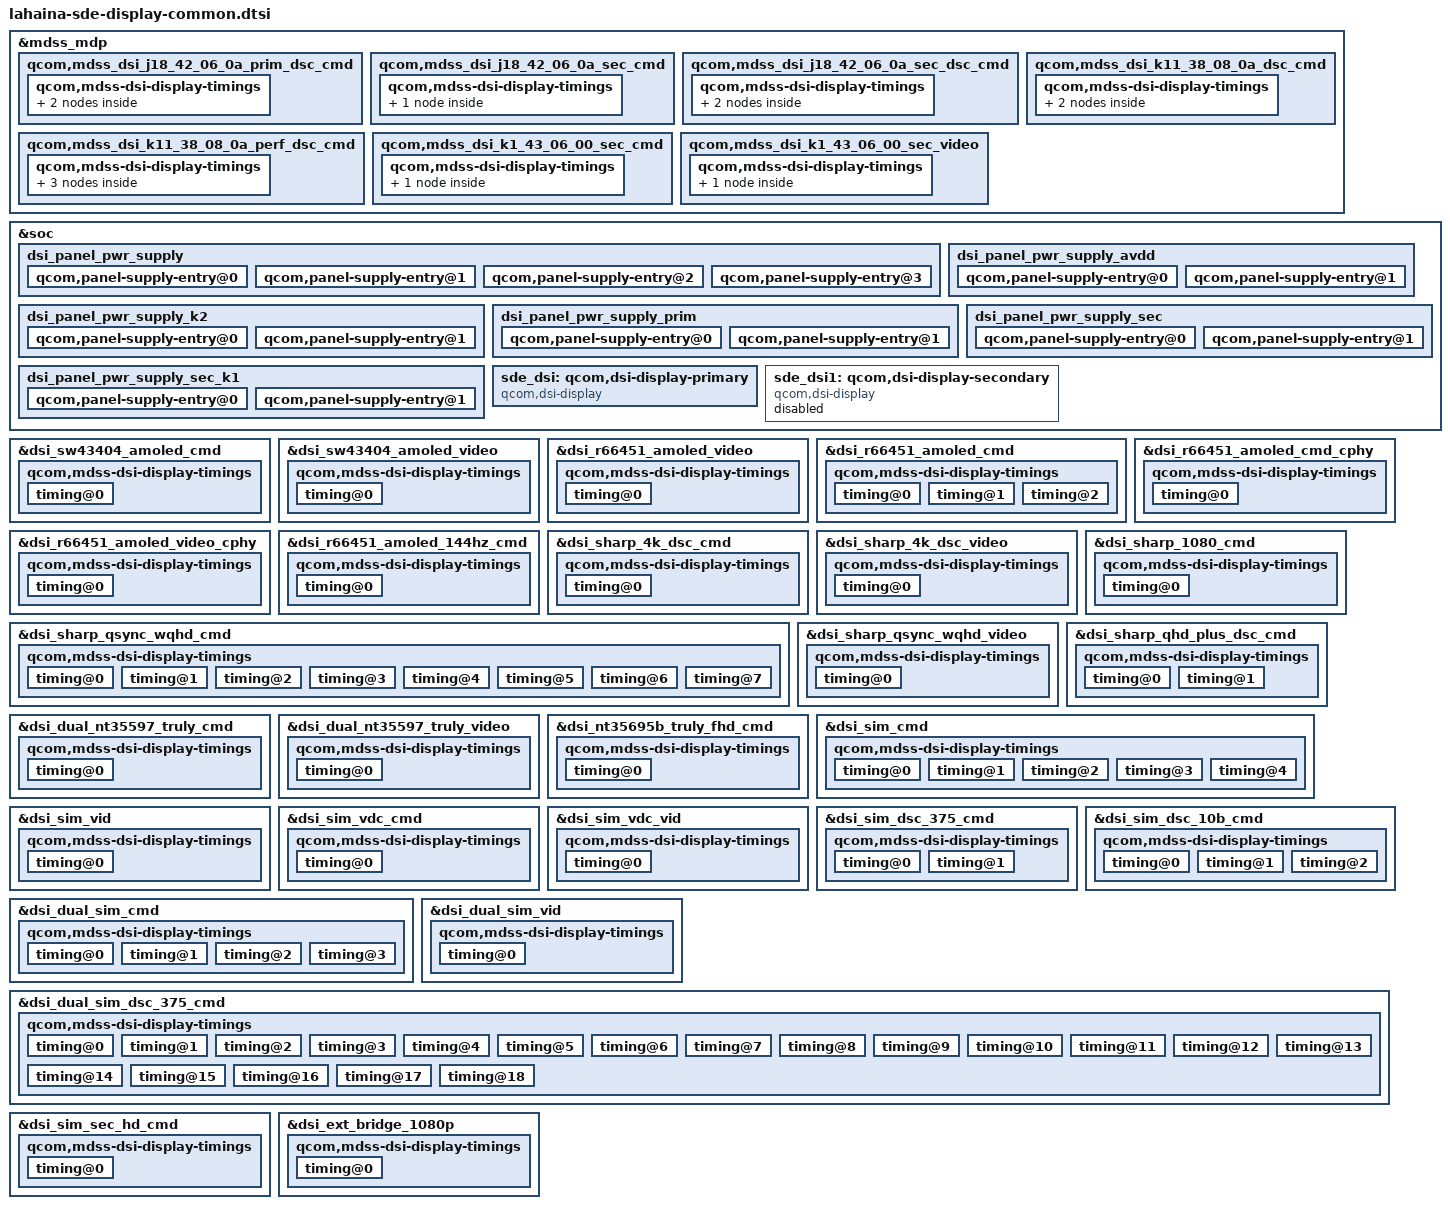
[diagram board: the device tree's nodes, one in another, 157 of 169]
#include "dsi-panel-sw43404-amoled-dsc-wqhd-cmd.dtsi"
#include "dsi-panel-sw43404-amoled-dsc-wqhd-video.dtsi"
#include "dsi-panel-sw43404-amoled-dsc-fhd-plus-cmd.dtsi"
#include "dsi-panel-sharp-dsc-4k-cmd.dtsi"
#include "dsi-panel-sharp-dsc-4k-video.dtsi"
#include "dsi-panel-sharp-dsc-qhd-plus-cmd.dtsi"
#include "dsi-panel-sharp-qsync-wqhd-cmd.dtsi"
#include "dsi-panel-sharp-qsync-wqhd-video.dtsi"
#include "dsi-panel-sharp-1080p-cmd.dtsi"
#include "dsi-panel-nt35597-truly-dualmipi-wqxga-cmd.dtsi"
#include "dsi-panel-nt35597-truly-dualmipi-wqxga-video.dtsi"
#include "dsi-panel-nt35695b-truly-fhd-cmd.dtsi"
#include "dsi-panel-nt35695b-truly-fhd-video.dtsi"
#include "dsi-panel-r66451-dsc-fhd-plus-video-cphy.dtsi"
#include "dsi-panel-r66451-dsc-fhd-plus-cmd-cphy.dtsi"
#include "dsi-panel-r66451-dsc-fhd-plus-video.dtsi"
#include "dsi-panel-r66451-dsc-fhd-plus-cmd.dtsi"
#include "dsi-panel-r66451-dsc-fhd-plus-144hz-cmd.dtsi"
#include "dsi-panel-ext-bridge-1080p.dtsi"
#include "dsi-panel-sim-cmd.dtsi"
#include "dsi-panel-sim-video.dtsi"
#include "dsi-panel-sim-dsc375-cmd.dtsi"
#include "dsi-panel-sim-dsc-10bit-cmd.dtsi"
#include "dsi-panel-sim-dualmipi-cmd.dtsi"
#include "dsi-panel-sim-dualmipi-video.dtsi"
#include "dsi-panel-sim-dualmipi-dsc375-cmd.dtsi"
#include "dsi-panel-sim-sec-hd-cmd.dtsi"
#include <dt-bindings/clock/mdss-5nm-pll-clk.h>
#include "dsi-panel-sim-vdc-vid.dtsi"
#include "dsi-panel-sim-vdc-cmd.dtsi"
#include "dsi-panel-k2-38-0c-00-dsc-cmd.dtsi"
#include "dsi-panel-k2-38-08-0a-dsc-cmd.dtsi"
#include "dsi-panel-k2-38-08-0a-mp-dsc-cmd.dtsi"
#include "dsi-panel-k2b-38-08-0a-dsc-cmd.dtsi"

&mdss_mdp {
	qcom,mdss_dsi_j18_42_06_0a_prim_dsc_cmd {
		qcom,mdss-dsi-panel-name = "xiaomi 42 06 0a cmd mode dsc primary dsi panel";
		qcom,mdss-dsi-panel-type = "dsi_cmd_mode";
		qcom,mdss-dsi-virtual-channel-id = <0x0>;
		qcom,mdss-dsi-stream = <0x0>;
		qcom,mdss-dsi-bpp = <0x18>;
		qcom,mdss-dsi-color-order = "rgb_swap_rgb";
		qcom,mdss-dsi-underflow-color = <0xff>;
		qcom,mdss-dsi-border-color = <0x0>;
		qcom,dsi-ctrl-num = <0x0>;
		qcom,dsi-phy-num = <0x0>;
		qcom,mdss-dsi-traffic-mode = "burst_mode";
		qcom,mdss-dsi-lane-map = "lane_map_0123";
		qcom,mdss-dsi-bllp-eof-power-mode;
		qcom,mdss-dsi-bllp-power-mode;
		qcom,mdss-dsi-lane-0-state;
		qcom,mdss-dsi-lane-1-state;
		qcom,mdss-dsi-lane-2-state;
		qcom,mdss-dsi-lane-3-state;
		qcom,mdss-dsi-dma-trigger = "trigger_sw";
		qcom,mdss-dsi-mdp-trigger = "none";
		qcom,mdss-dsi-reset-sequence = <0x1 0x1 0x0 0x1 0x1 0xf>;
		qcom,mdss-pan-physical-width-dimension = <0x7a>;
		qcom,mdss-pan-physical-height-dimension = <0xa3>;
		qcom,mdss-dsi-te-pin-select = <0x1>;
		qcom,mdss-dsi-wr-mem-start = <0x2c>;
		qcom,mdss-dsi-wr-mem-continue = <0x3c>;
		qcom,mdss-dsi-te-dcs-command = <0x1>;
		qcom,mdss-dsi-te-check-enable;
		qcom,mdss-dsi-te-using-te-pin;
		qcom,mdss-dsi-tx-eot-append;
		qcom,mdss-dsi-lp11-init;
		qcom,mdss-dsi-bl-inverted-dbv;
		qcom,mdss-dsi-panel-hdr-enabled;
		qcom,mdss-dsi-panel-hdr-color-primaries = <0x38a4 0x3c8c 0x7d00 0x4268 0x3c8c 0x7530 0x1f40 0xbb8>;
		qcom,mdss-dsi-panel-peak-brightness = <0x401640>;
		qcom,mdss-dsi-panel-blackness-level = <0xc9e>;
		qcom,bl-update-flag = "delay_until_first_frame";
		mi,aod-bl-51ctl-flag;
		mi,esd-err-irq-gpio = <0xffffffff 0x43 0x2001>;
		qcom,dsi-select-clocks = "mux_byte_clk0", "mux_pixel_clk0";
		qcom,panel-supply-entries = <0x23>;
		qcom,mdss-dsi-bl-pmic-control-type = "bl_ctrl_dcs";
		qcom,mdss-dsi-bl-min-level = <0x2>;
		qcom,mdss-dsi-bl-max-level = <0x7ff>;
		qcom,mdss-brightness-max-level = <0x7ff>;
		qcom,platform-te-gpio = <0xffffffff 0x52 0x0>;
		qcom,platform-reset-gpio = <0xffffffff 0x18 0x0>;

		qcom,mdss-dsi-display-timings {

			timing@0 {
				qcom,mdss-dsi-panel-framerate = <0x3c>;
				qcom,mdss-dsi-panel-width = <0x9b0>;
				qcom,mdss-dsi-panel-height = <0x744>;
				qcom,mdss-dsi-h-front-porch = <0xc>;
				qcom,mdss-dsi-h-back-porch = <0xc>;
				qcom,mdss-dsi-h-pulse-width = <0x4>;
				qcom,mdss-dsi-h-sync-skew = <0x0>;
				qcom,mdss-dsi-v-back-porch = <0x7>;
				qcom,mdss-dsi-v-front-porch = <0x17>;
				qcom,mdss-dsi-v-pulse-width = <0x2>;
				qcom,mdss-dsi-h-sync-pulse = <0x0>;
				qcom,mdss-dsi-h-left-border = <0x0>;
				qcom,mdss-dsi-h-right-border = <0x0>;
				qcom,mdss-dsi-v-top-border = <0x0>;
				qcom,mdss-dsi-v-bottom-border = <0x0>;
				qcom,mdss-dsi-panel-clockrate = <0x23c34600>;
				qcom,mdss-dsi-panel-jitter = <0x5 0x1>;
				qcom,mdss-dsi-on-command = [15 00 00 00 00 00 02 fe 00 15 00 00 00 00 00 02 fa 01 15 00 00 00 00 00 02 fe 40 15 00 00 00 00 00 02 40 06 15 00 00 00 00 00 02 fe d2 15 00 00 00 00 00 02 36 83 15 00 00 00 00 00 02 37 0c 15 00 00 00 00 00 02 fe 00 15 00 00 00 00 00 02 c2 08 15 00 00 00 00 00 02 35 00 39 01 00 00 00 00 03 51 07 ff 05 01 00 00 78 00 02 11 00 05 01 00 00 1e 00 02 29 00];
				qcom,mdss-dsi-off-command = [05 01 00 00 0a 00 02 28 00 05 01 00 00 78 00 02 10 00];
				qcom,mdss-dsi-on-command-state = "dsi_lp_mode";
				qcom,mdss-dsi-off-command-state = "dsi_lp_mode";
				qcom,mdss-dsi-lp1-command = [05 01 00 00 00 00 02 39 00];
				qcom,mdss-dsi-lp1-command-state = "dsi_lp_mode";
				qcom,mdss-dsi-nolp-command = [05 01 00 00 00 00 02 38 00];
				qcom,mdss-dsi-nolp-command-state = "dsi_lp_mode";
				qcom,compression-mode = "dsc";
				qcom,mdss-dsc-slice-height = <0x3a2>;
				qcom,mdss-dsc-slice-width = <0x4d8>;
				qcom,mdss-dsc-slice-per-pkt = <0x2>;
				qcom,mdss-dsc-bit-per-component = <0x8>;
				qcom,mdss-dsc-bit-per-pixel = <0x8>;
				qcom,mdss-dsc-block-prediction-enable;
				mi,mdss-dsi-flat-on-command = [39 00 00 00 00 00 02 fe 98 39 00 00 00 00 00 02 17 fe 39 00 00 00 00 00 02 18 7f 39 00 00 00 00 00 02 27 20 39 00 00 00 00 00 02 fe 40 39 00 00 00 00 00 02 bd 05 39 00 00 00 00 00 02 fe f2 39 00 00 00 00 00 02 e0 00 39 00 00 00 00 00 02 fe 98 39 00 00 00 00 00 02 18 7f 39 01 00 00 00 00 02 1c 04];
				mi,mdss-dsi-flat-off-command = [39 00 00 00 00 00 02 fe 98 39 00 00 00 00 00 02 17 fe 39 00 00 00 00 00 02 18 7f 39 00 00 00 00 00 02 27 20 39 00 00 00 00 00 02 fe 40 39 00 00 00 00 00 02 bd 00 39 00 00 00 00 00 02 fe f2 39 00 00 00 00 00 02 e0 00 39 00 00 00 00 00 02 fe 98 39 00 00 00 00 00 02 18 7f 39 01 00 00 00 00 02 1c 00];
				mi,mdss-dsi-flat-on-command-state = "dsi_hs_mode";
				mi,mdss-dsi-flat-off-command-state = "dsi_hs_mode";
				qcom,mdss-dsi-panel-phy-timings = [00 15 05 05 14 1f 05 05 06 02 04 00 13 0a];
				qcom,display-topology = <0x2 0x2 0x1>;
				qcom,default-topology-index = <0x0>;
			};

			timing@1 {
				qcom,mdss-dsi-panel-framerate = <0x5a>;
				qcom,mdss-dsi-panel-width = <0x9b0>;
				qcom,mdss-dsi-panel-height = <0x744>;
				qcom,mdss-dsi-h-front-porch = <0xc>;
				qcom,mdss-dsi-h-back-porch = <0xc>;
				qcom,mdss-dsi-h-pulse-width = <0x4>;
				qcom,mdss-dsi-h-sync-skew = <0x0>;
				qcom,mdss-dsi-v-back-porch = <0x6>;
				qcom,mdss-dsi-v-front-porch = <0x17>;
				qcom,mdss-dsi-v-pulse-width = <0x2>;
				qcom,mdss-dsi-h-sync-pulse = <0x0>;
				qcom,mdss-dsi-h-left-border = <0x0>;
				qcom,mdss-dsi-h-right-border = <0x0>;
				qcom,mdss-dsi-v-top-border = <0x0>;
				qcom,mdss-dsi-v-bottom-border = <0x0>;
				qcom,mdss-dsi-panel-clockrate = <0x23c34600>;
				qcom,mdss-dsi-panel-jitter = <0x5 0x1>;
				qcom,mdss-dsi-on-command = [15 00 00 00 00 00 02 fe 00 15 00 00 00 00 00 02 fa 01 15 00 00 00 00 00 02 fe 40 15 00 00 00 00 00 02 40 06 15 00 00 00 00 00 02 fe d2 15 00 00 00 00 00 02 36 83 15 00 00 00 00 00 02 37 0c 15 00 00 00 00 00 02 fe 00 15 00 00 00 00 00 02 c2 08 15 00 00 00 00 00 02 35 00 39 01 00 00 00 00 03 51 07 ff 05 01 00 00 78 00 02 11 00 05 01 00 00 1e 00 02 29 00];
				qcom,mdss-dsi-off-command = [05 01 00 00 0a 00 02 28 00 05 01 00 00 78 00 02 10 00];
				qcom,mdss-dsi-on-command-state = "dsi_lp_mode";
				qcom,mdss-dsi-off-command-state = "dsi_lp_mode";
				qcom,mdss-dsi-lp1-command = [05 01 00 00 00 00 02 39 00];
				qcom,mdss-dsi-lp1-command-state = "dsi_lp_mode";
				qcom,mdss-dsi-nolp-command = [05 01 00 00 00 00 02 38 00];
				qcom,mdss-dsi-nolp-command-state = "dsi_lp_mode";
				qcom,compression-mode = "dsc";
				qcom,mdss-dsc-slice-height = <0x3a2>;
				qcom,mdss-dsc-slice-width = <0x4d8>;
				qcom,mdss-dsc-slice-per-pkt = <0x2>;
				qcom,mdss-dsc-bit-per-component = <0x8>;
				qcom,mdss-dsc-bit-per-pixel = <0x8>;
				qcom,mdss-dsc-block-prediction-enable;
				qcom,mdss-dsi-panel-phy-timings = [00 15 05 05 14 1f 05 05 06 02 04 00 13 0a];
				qcom,display-topology = <0x2 0x2 0x1>;
				qcom,default-topology-index = <0x0>;
			};
		};
	};

	qcom,mdss_dsi_j18_42_06_0a_sec_cmd {
		qcom,mdss-dsi-panel-name = "xiaomi 42 06 0a cmd mode secondary dsi panel";
		qcom,mdss-dsi-panel-type = "dsi_cmd_mode";
		qcom,mdss-dsi-virtual-channel-id = <0x0>;
		qcom,mdss-dsi-stream = <0x0>;
		qcom,mdss-dsi-bpp = <0x18>;
		qcom,mdss-dsi-color-order = "rgb_swap_rgb";
		qcom,mdss-dsi-underflow-color = <0xff>;
		qcom,mdss-dsi-border-color = <0x0>;
		qcom,dsi-sec-ctrl-num = <0x1>;
		qcom,dsi-sec-phy-num = <0x1>;
		qcom,mdss-dsi-traffic-mode = "burst_mode";
		qcom,mdss-dsi-lane-map = "lane_map_0123";
		qcom,mdss-dsi-bllp-eof-power-mode;
		qcom,mdss-dsi-bllp-power-mode;
		qcom,mdss-dsi-lane-0-state;
		qcom,mdss-dsi-lane-1-state;
		qcom,mdss-dsi-lane-2-state;
		qcom,mdss-dsi-lane-3-state;
		qcom,mdss-dsi-dma-trigger = "trigger_sw";
		qcom,mdss-dsi-mdp-trigger = "none";
		qcom,mdss-dsi-reset-sequence = <0x1 0x1 0x0 0x1 0x1 0xf>;
		qcom,mdss-pan-physical-width-dimension = <0x34>;
		qcom,mdss-pan-physical-height-dimension = <0x9d>;
		qcom,mdss-dsi-te-pin-select = <0x1>;
		qcom,mdss-dsi-wr-mem-start = <0x2c>;
		qcom,mdss-dsi-wr-mem-continue = <0x3c>;
		qcom,mdss-dsi-te-dcs-command = <0x1>;
		qcom,mdss-dsi-te-check-enable;
		qcom,mdss-dsi-te-using-te-pin;
		qcom,mdss-dsi-tx-eot-append;
		qcom,mdss-dsi-lp11-init;
		qcom,mdss-dsi-bl-inverted-dbv;
		qcom,mdss-dsi-panel-hdr-enabled;
		qcom,mdss-dsi-panel-hdr-color-primaries = <0x38a4 0x3c8c 0x7d00 0x4268 0x3c8c 0x7530 0x1f40 0xbb8>;
		qcom,mdss-dsi-panel-peak-brightness = <0x401640>;
		qcom,mdss-dsi-panel-blackness-level = <0xc9e>;
		qcom,bl-update-flag = "delay_until_first_frame";
		qcom,dsi-select-sec-clocks = "mux_byte_clk1", "mux_pixel_clk1";
		qcom,panel-sec-supply-entries = <0x24>;
		qcom,mdss-dsi-sec-bl-pmic-control-type = "bl_ctrl_dcs";
		qcom,mdss-dsi-bl-min-level = <0x2>;
		qcom,mdss-dsi-bl-max-level = <0x7ff>;
		qcom,mdss-brightness-max-level = <0x7ff>;
		qcom,platform-te-gpio = <0xffffffff 0x53 0x0>;
		qcom,platform-sec-reset-gpio = <0xffffffff 0x4a 0x0>;

		qcom,mdss-dsi-display-timings {

			timing@0 {
				qcom,mdss-dsi-panel-framerate = <0x3c>;
				qcom,mdss-dsi-panel-width = <0x348>;
				qcom,mdss-dsi-panel-height = <0x9d8>;
				qcom,mdss-dsi-h-front-porch = <0x1c>;
				qcom,mdss-dsi-h-back-porch = <0x24>;
				qcom,mdss-dsi-h-pulse-width = <0x4>;
				qcom,mdss-dsi-h-sync-skew = <0x0>;
				qcom,mdss-dsi-v-back-porch = <0x14>;
				qcom,mdss-dsi-v-front-porch = <0x10>;
				qcom,mdss-dsi-v-pulse-width = <0x4>;
				qcom,mdss-dsi-h-sync-pulse = <0x0>;
				qcom,mdss-dsi-h-left-border = <0x0>;
				qcom,mdss-dsi-h-right-border = <0x0>;
				qcom,mdss-dsi-v-top-border = <0x0>;
				qcom,mdss-dsi-v-bottom-border = <0x0>;
				qcom,mdss-dsi-panel-clockrate = <0x338bcd00>;
				qcom,mdss-dsi-panel-jitter = <0x5 0x1>;
				qcom,mdss-dsi-on-command = [39 00 00 00 00 00 02 fe 60 39 00 00 00 00 00 02 95 ca 39 00 00 00 00 00 02 fe 00 39 00 00 00 00 00 02 5e 01 39 00 00 00 00 00 02 c2 08 39 00 00 00 00 00 02 35 00 39 01 00 00 00 00 03 51 07 ff 05 01 00 00 78 00 02 11 00 05 01 00 00 1e 00 02 29 00];
				qcom,mdss-dsi-off-command = [05 01 00 00 14 00 02 28 00 05 01 00 00 78 00 02 10 00];
				qcom,mdss-dsi-on-command-state = "dsi_lp_mode";
				qcom,mdss-dsi-off-command-state = "dsi_lp_mode";
				qcom,mdss-dsi-panel-phy-timings = [00 1d 07 07 17 22 07 07 08 02 04 00 19 0c];
				qcom,display-topology = <0x1 0x0 0x1>;
				qcom,default-topology-index = <0x0>;
			};
		};
	};

	qcom,mdss_dsi_j18_42_06_0a_sec_dsc_cmd {
		qcom,mdss-dsi-panel-name = "xiaomi 42 06 0a cmd mode dsc secondary dsi panel";
		qcom,mdss-dsi-panel-type = "dsi_cmd_mode";
		qcom,mdss-dsi-virtual-channel-id = <0x0>;
		qcom,mdss-dsi-stream = <0x0>;
		qcom,mdss-dsi-bpp = <0x18>;
		qcom,mdss-dsi-color-order = "rgb_swap_rgb";
		qcom,mdss-dsi-underflow-color = <0xff>;
		qcom,mdss-dsi-border-color = <0x0>;
		qcom,dsi-sec-ctrl-num = <0x1>;
		qcom,dsi-sec-phy-num = <0x1>;
		qcom,mdss-dsi-traffic-mode = "burst_mode";
		qcom,mdss-dsi-lane-map = "lane_map_0123";
		qcom,mdss-dsi-bllp-eof-power-mode;
		qcom,mdss-dsi-bllp-power-mode;
		qcom,mdss-dsi-lane-0-state;
		qcom,mdss-dsi-lane-1-state;
		qcom,mdss-dsi-lane-2-state;
		qcom,mdss-dsi-lane-3-state;
		qcom,mdss-dsi-dma-trigger = "trigger_sw";
		qcom,mdss-dsi-mdp-trigger = "none";
		qcom,mdss-dsi-reset-sequence = <0x1 0x1 0x0 0x1 0x1 0xf>;
		qcom,mdss-pan-physical-width-dimension = <0x34>;
		qcom,mdss-pan-physical-height-dimension = <0x9d>;
		qcom,mdss-dsi-te-pin-select = <0x1>;
		qcom,mdss-dsi-wr-mem-start = <0x2c>;
		qcom,mdss-dsi-wr-mem-continue = <0x3c>;
		qcom,mdss-dsi-te-dcs-command = <0x1>;
		qcom,mdss-dsi-te-check-enable;
		qcom,mdss-dsi-te-using-te-pin;
		qcom,mdss-dsi-tx-eot-append;
		qcom,mdss-dsi-lp11-init;
		qcom,mdss-dsi-bl-inverted-dbv;
		qcom,mdss-dsi-panel-hdr-enabled;
		qcom,mdss-dsi-panel-hdr-color-primaries = <0x38a4 0x3c8c 0x7d00 0x4268 0x3c8c 0x7530 0x1f40 0xbb8>;
		qcom,mdss-dsi-panel-peak-brightness = <0x401640>;
		qcom,mdss-dsi-panel-blackness-level = <0xc9e>;
		qcom,bl-update-flag = "delay_until_first_frame";
		mi,esd-err-irq-gpio = <0xffffffff 0x4b 0x2001>;
		mi,aod-nolp-command-enabled;
		mi,aod-bl-51ctl-flag;
		mi,mdss-dsi-panel-bl-dfps-enabled;
		mi,mdss-dsi-panel-bl-dfps-switch-threshold = <0x3b8>;
		mi,mdss-dsi-panel-dc-type = <0x0>;
		qcom,dsi-select-sec-clocks = "mux_byte_clk1", "mux_pixel_clk1";
		qcom,panel-sec-supply-entries = <0x24>;
		qcom,mdss-dsi-sec-bl-pmic-control-type = "bl_ctrl_dcs";
		qcom,mdss-dsi-bl-min-level = <0x2>;
		qcom,mdss-dsi-bl-max-level = <0x7ff>;
		qcom,mdss-brightness-max-level = <0x7ff>;
		qcom,platform-te-gpio = <0xffffffff 0x53 0x0>;
		qcom,platform-sec-reset-gpio = <0xffffffff 0x4a 0x0>;

		qcom,mdss-dsi-display-timings {

			timing@0 {
				qcom,mdss-dsi-panel-framerate = <0x3c>;
				qcom,mdss-dsi-panel-width = <0x348>;
				qcom,mdss-dsi-panel-height = <0x9d8>;
				qcom,mdss-dsi-h-front-porch = <0x1c>;
				qcom,mdss-dsi-h-back-porch = <0x24>;
				qcom,mdss-dsi-h-pulse-width = <0x4>;
				qcom,mdss-dsi-h-sync-skew = <0x0>;
				qcom,mdss-dsi-v-back-porch = <0x14>;
				qcom,mdss-dsi-v-front-porch = <0x10>;
				qcom,mdss-dsi-v-pulse-width = <0x4>;
				qcom,mdss-dsi-h-sync-pulse = <0x0>;
				qcom,mdss-dsi-h-left-border = <0x0>;
				qcom,mdss-dsi-h-right-border = <0x0>;
				qcom,mdss-dsi-v-top-border = <0x0>;
				qcom,mdss-dsi-v-bottom-border = <0x0>;
				qcom,mdss-dsi-panel-clockrate = <0x338bcd00>;
				qcom,mdss-dsi-panel-jitter = <0x5 0x1>;
				qcom,mdss-dsi-on-command = [39 00 00 00 00 00 02 fe 00 39 00 00 00 00 00 02 fa 01 39 00 00 00 00 00 02 fe e0 39 00 00 00 00 00 02 e7 00 39 00 00 00 00 00 02 fe d0 39 00 00 00 00 00 02 70 81 39 00 00 00 00 00 02 fe 60 39 00 00 00 00 00 02 c3 00 39 00 00 00 00 00 02 fe 74 39 00 00 00 00 00 02 0e ff 39 00 00 00 00 00 02 0f 00 39 00 00 00 00 00 02 10 14 39 00 00 00 00 00 02 11 14 39 00 00 00 00 00 02 12 13 39 00 00 00 00 00 02 13 12 39 00 00 00 00 00 02 14 11 39 00 00 00 00 00 02 15 10 39 00 00 00 00 00 02 16 0f 39 00 00 00 00 00 02 17 0e 39 00 00 00 00 00 02 18 0d 39 00 00 00 00 00 02 19 0c 39 00 00 00 00 00 02 fe 00 39 00 00 00 00 00 02 5e 01 39 00 00 00 00 00 02 c2 08 39 00 00 00 00 00 02 35 00 39 01 00 00 00 00 03 51 07 ff 05 01 00 00 78 00 02 11 00 05 01 00 00 1e 00 02 29 00];
				qcom,mdss-dsi-off-command = [05 01 00 00 14 00 02 28 00 05 01 00 00 78 00 02 10 00];
				qcom,mdss-dsi-on-command-state = "dsi_lp_mode";
				qcom,mdss-dsi-off-command-state = "dsi_lp_mode";
				qcom,mdss-dsi-timing-switch-command = [39 00 00 00 00 00 02 fe d0 39 00 00 00 00 00 02 70 81 39 00 00 00 00 00 02 fe 60 39 00 00 00 00 00 02 c3 00 39 00 00 00 00 00 02 fe 74 39 00 00 00 00 00 02 0e ff 39 00 00 00 00 00 02 0f 00 39 00 00 00 00 00 02 10 14 39 00 00 00 00 00 02 11 14 39 00 00 00 00 00 02 12 13 39 00 00 00 00 00 02 13 12 39 00 00 00 00 00 02 14 11 39 00 00 00 00 00 02 15 10 39 00 00 00 00 00 02 16 0f 39 00 00 00 00 00 02 17 0e 39 00 00 00 00 00 02 18 0d 39 00 00 00 00 00 02 19 0c 39 01 00 00 00 00 02 fe 00];
				qcom,mdss-dsi-timing-switch-command-state = "dsi_lp_mode";
				qcom,mdss-dsi-lp1-command = <0x39000000 0x2fe 0x60390000 0x2 0xc3003900 0x0 0x2fe0015 0x1000000 0x23900>;
				qcom,mdss-dsi-lp1-command-state = "dsi_lp_mode";
				qcom,mdss-dsi-nolp-command = [39 00 00 00 00 00 02 fe 00 15 00 00 00 00 00 02 38 00 39 00 00 00 00 00 02 fe 60 39 00 00 00 00 00 02 c3 00 39 01 00 00 00 00 02 fe 00];
				qcom,mdss-dsi-nolp-command-state = "dsi_lp_mode";
				qcom,compression-mode = "dsc";
				qcom,mdss-dsc-slice-height = <0x1a4>;
				qcom,mdss-dsc-slice-width = <0x348>;
				qcom,mdss-dsc-slice-per-pkt = <0x2>;
				qcom,mdss-dsc-bit-per-component = <0x8>;
				qcom,mdss-dsc-bit-per-pixel = <0x8>;
				qcom,mdss-dsc-block-prediction-enable;
				mi,mdss-dsi-timing-switch-command = [39 00 00 00 00 00 02 fe d0 39 00 00 00 00 00 02 70 81 39 00 00 00 00 00 02 fe 60 39 00 00 00 00 00 02 c3 08 39 00 00 00 00 00 02 fe 74 39 00 00 00 00 00 02 0e ff 39 00 00 00 00 00 02 0f 00 39 00 00 00 00 00 02 10 14 39 00 00 00 00 00 02 11 14 39 00 00 00 00 00 02 12 13 39 00 00 00 00 00 02 13 12 39 00 00 00 00 00 02 14 11 39 00 00 00 00 00 02 15 10 39 00 00 00 00 00 02 16 0f 39 00 00 00 00 00 02 17 0e 39 00 00 00 00 00 02 18 0d 39 00 00 00 00 00 02 19 0c 39 01 00 00 00 00 02 fe 00];
				mi,mdss-dsi-timing-switch-command-state = "dsi_lp_mode";
				mi,mdss-dsi-timing-switch-dc-lbm-command = <0x39000000 0x2fe 0x60390000 0x2 0xc3083900 0x0 0x2fe7439 0x0 0x20000 0x39000000 0x201 0x390000 0x2 0x2113900 0x0 0x2037339 0x0 0x2040f 0x39000000 0x205 0xa390000 0x2 0x6263900 0x0 0x2075f39 0x0 0x208be 0x39000000 0x209 0x1d390000 0x2 0xadc3900 0x0 0x20bb839 0x0 0x20cff 0x39000000 0x20d 0xff390000 0x2 0xeff3900 0x0 0x20f0039 0x0 0x21009 0x39000000 0x211 0x9390000 0x2 0x12083900 0x0 0x2130739 0x0 0x21406 0x39000000 0x215 0x5390000 0x2 0x16043900 0x0 0x2170339 0x0 0x21802 0x39000000 0x219 0x1390000 0x2 0x22ff3900 0x0 0x243ff39 0x0 0x24400 0x39000000 0x245 0x11390000 0x2 0x46113900 0x0 0x2474239 0x0 0x248f7 0x39000000 0x249 0xff390000 0x2 0x4a1f3900 0x0 0x24b1f39 0x0 0x24c1f 0x39000000 0x24d 0x1f390000 0x2 0x4ebc3900 0x0 0x24f5e39 0x0 0x2509e 0x39000000 0x251 0xff390000 0x2 0x52ff3900 0x0 0x253ff39 0x0 0x261ff 0x39000000 0x2fe 0x20390000 0x2 0xba053900 0x0 0x25d0239 0x0 0x2753f 0x39000000 0x276 0x3f390000 0x2 0x773f3900 0x0 0x2785a39 0x0 0x27a5a 0x39000000 0x27b 0x67390000 0x2 0x7c703901 0x0 0x27d7739 0x0 0x2fed0 0x39000000 0x270 0x81390000 0x2 0xfe603900 0x0 0x2c30839 0x0 0x2fe74 0x39000000 0x20e 0xff390000 0x2 0xf003900 0x0 0x2101439 0x0 0x21114 0x39000000 0x212 0x13390000 0x2 0x13123900 0x0 0x2141139 0x0 0x21510 0x39000000 0x216 0xf390000 0x2 0x170e3900 0x0 0x2180d39 0x1000000 0x2190c 0x39000000 0x2fe 0x60390000 0x2 0xc3003900 0x0 0x2fe7439 0x0 0x20000 0x39000000 0x201 0x390000 0x2 0x2003900 0x0 0x2037039 0x0 0x2040f 0x39000000 0x205 0x390000 0x2 0x6003900 0x0 0x2070039 0x0 0x20800 0x39000000 0x209 0x390000 0x2 0xa003900 0x0 0x20b0039 0x0 0x20cff 0x39000000 0x20d 0xff390000 0x2 0xe803900 0x0 0x20f0039 0x0 0x2100d 0x39000000 0x211 0x390000 0x2 0x12003900 0x0 0x2130039 0x0 0x21400 0x39000000 0x215 0x390000 0x2 0x16003900 0x0 0x2170039 0x0 0x2180d 0x39000000 0x219 0xc390000 0x2 0x22803900 0x0 0x2438039 0x0 0x24400 0x39000000 0x245 0xff390000 0x2 0x46ff3900 0x0 0x247ff39 0x0 0x248ff 0x39000000 0x249 0xff390000 0x2 0x4aff3900 0x0 0x24bff39 0x0 0x24cff 0x39000000 0x24d 0xff390000 0x2 0x4eff3900 0x0 0x24fff39 0x0 0x250ff 0x39000000 0x251 0xff390000 0x2 0x52ff3900 0x0 0x253ff39 0x0 0x26180 0x39000000 0x2fe 0x20390000 0x2 0xba033900 0x0 0x25d0239 0x0 0x2757f 0x39000000 0x276 0x7f390000 0x2 0x777f3900 0x0 0x2787f39 0x0 0x27a7f 0x39000000 0x27b 0x7f390000 0x2 0x7c7f3900 0x0 0x27d7f39 0x1000000 0x2fe00>;
				mi,mdss-dsi-timing-switch-dc-lbm-command-state = "dsi_lp_mode";
				mi,mdss-dsi-timing-switch-dc-hbm-command = <0x39000000 0x2fe 0x60390000 0x2 0xc3083900 0x0 0x2fe7439 0x0 0x20000 0x39000000 0x201 0x390000 0x2 0x2113900 0x0 0x2037339 0x0 0x2040f 0x39000000 0x205 0xa390000 0x2 0x6263900 0x0 0x2075f39 0x0 0x208be 0x39000000 0x209 0x1d390000 0x2 0xadc3900 0x0 0x20bb839 0x0 0x20cff 0x39000000 0x20d 0xff390000 0x2 0xeff3900 0x0 0x20f0039 0x0 0x21009 0x39000000 0x211 0x9390000 0x2 0x12083900 0x0 0x2130739 0x0 0x21406 0x39000000 0x215 0x5390000 0x2 0x16043900 0x0 0x2170339 0x0 0x21802 0x39000000 0x219 0x1390000 0x2 0x22ff3900 0x0 0x243ff39 0x0 0x24400 0x39000000 0x245 0x11390000 0x2 0x46113900 0x0 0x2474239 0x0 0x248f7 0x39000000 0x249 0xff390000 0x2 0x4a1f3900 0x0 0x24b1f39 0x0 0x24c1f 0x39000000 0x24d 0x1f390000 0x2 0x4ebc3900 0x0 0x24f5e39 0x0 0x2509e 0x39000000 0x251 0xff390000 0x2 0x52ff3900 0x0 0x253ff39 0x0 0x261ff 0x39000000 0x2fe 0x20390000 0x2 0xba053900 0x0 0x25d0239 0x0 0x2753f 0x39000000 0x276 0x3f390000 0x2 0x773f3900 0x0 0x2785a39 0x0 0x27a5a 0x39000000 0x27b 0x67390000 0x2 0x7c703901 0x0 0x27d7739 0x0 0x2fed0 0x39000000 0x270 0x81390000 0x2 0xfe603900 0x0 0x2c30039 0x0 0x2fe74 0x39000000 0x20e 0xff390000 0x2 0xf003900 0x0 0x2101439 0x0 0x21114 0x39000000 0x212 0x13390000 0x2 0x13123900 0x0 0x2141139 0x0 0x21510 0x39000000 0x216 0xf390000 0x2 0x170e3900 0x0 0x2180d39 0x1000000 0x2190c 0x39000000 0x2fe 0x60390000 0x2 0xc3003900 0x0 0x2fe7439 0x0 0x20000 0x39000000 0x201 0x390000 0x2 0x2003900 0x0 0x2037039 0x0 0x2040f 0x39000000 0x205 0x390000 0x2 0x6003900 0x0 0x2070039 0x0 0x20800 0x39000000 0x209 0x390000 0x2 0xa003900 0x0 0x20b0039 0x0 0x20cff 0x39000000 0x20d 0xff390000 0x2 0xe803900 0x0 0x20f0039 0x0 0x2100d 0x39000000 0x211 0x390000 0x2 0x12003900 0x0 0x2130039 0x0 0x21400 0x39000000 0x215 0x390000 0x2 0x16003900 0x0 0x2170039 0x0 0x2180d 0x39000000 0x219 0xc390000 0x2 0x22803900 0x0 0x2438039 0x0 0x24400 0x39000000 0x245 0xff390000 0x2 0x46ff3900 0x0 0x247ff39 0x0 0x248ff 0x39000000 0x249 0xff390000 0x2 0x4aff3900 0x0 0x24bff39 0x0 0x24cff 0x39000000 0x24d 0xff390000 0x2 0x4eff3900 0x0 0x24fff39 0x0 0x250ff 0x39000000 0x251 0xff390000 0x2 0x52ff3900 0x0 0x253ff39 0x0 0x26180 0x39000000 0x2fe 0x20390000 0x2 0xba033900 0x0 0x25d0239 0x0 0x2757f 0x39000000 0x276 0x7f390000 0x2 0x777f3900 0x0 0x2787f39 0x0 0x27a7f 0x39000000 0x27b 0x7f390000 0x2 0x7c7f3900 0x0 0x27d7f39 0x1000000 0x2fe00>;
				mi,mdss-dsi-timing-switch-dc-hbm-command-state = "dsi_lp_mode";
				mi,mdss-dsi-bl-extpulse-on-command = [39 00 00 00 00 00 02 fe 60 39 00 00 00 00 00 02 c3 08 39 01 00 00 00 00 02 fe 00];
				mi,mdss-dsi-bl-extpulse-on-command-state = "dsi_lp_mode";
				mi,mdss-dsi-bl-extpulse-off-command = [39 00 00 00 00 00 02 fe 60 39 00 00 00 00 00 02 c3 00 39 01 00 00 00 00 02 fe 00];
				mi,mdss-dsi-bl-extpulse-off-command-state = "dsi_lp_mode";
				mi,mdss-dsi-dc-on-command = <0x39000000 0x2fe 0x60390000 0x2 0xc3003900 0x0 0x2fe7439 0x0 0x20000 0x39000000 0x201 0x390000 0x2 0x2003900 0x0 0x2037039 0x0 0x2040f 0x39000000 0x205 0x390000 0x2 0x6003900 0x0 0x2070039 0x0 0x20800 0x39000000 0x209 0x390000 0x2 0xa003900 0x0 0x20b0039 0x0 0x20cff 0x39000000 0x20d 0xff390000 0x2 0xe803900 0x0 0x20f0039 0x0 0x2100d 0x39000000 0x211 0x390000 0x2 0x12003900 0x0 0x2130039 0x0 0x21400 0x39000000 0x215 0x390000 0x2 0x16003900 0x0 0x2170039 0x0 0x2180d 0x39000000 0x219 0xc390000 0x2 0x22803900 0x0 0x2438039 0x0 0x24400 0x39000000 0x245 0xff390000 0x2 0x46ff3900 0x0 0x247ff39 0x0 0x248ff 0x39000000 0x249 0xff390000 0x2 0x4aff3900 0x0 0x24bff39 0x0 0x24cff 0x39000000 0x24d 0xff390000 0x2 0x4eff3900 0x0 0x24fff39 0x0 0x250ff 0x39000000 0x251 0xff390000 0x2 0x52ff3900 0x0 0x253ff39 0x0 0x26180 0x39000000 0x2fe 0x20390000 0x2 0xba033900 0x0 0x25d0239 0x0 0x2757f 0x39000000 0x276 0x7f390000 0x2 0x777f3900 0x0 0x2787f39 0x0 0x27a7f 0x39000000 0x27b 0x7f390000 0x2 0x7c7f3900 0x0 0x27d7f39 0x1000000 0x2fe00>;
				mi,mdss-dsi-dc-on-command-state = "dsi_lp_mode";
				mi,mdss-dsi-dc-off-command = [39 00 00 00 00 00 02 fe 74 39 00 00 00 00 00 02 00 00 39 00 00 00 00 00 02 01 00 39 00 00 00 00 00 02 02 11 39 00 00 00 00 00 02 03 73 39 00 00 00 00 00 02 04 0f 39 00 00 00 00 00 02 05 0a 39 00 00 00 00 00 02 06 26 39 00 00 00 00 00 02 07 5f 39 00 00 00 00 00 02 08 be 39 00 00 00 00 00 02 09 1d 39 00 00 00 00 00 02 0a dc 39 00 00 00 00 00 02 0b b8 39 00 00 00 00 00 02 0c ff 39 00 00 00 00 00 02 0d ff 39 00 00 00 00 00 02 0e ff 39 00 00 00 00 00 02 0f 00 39 00 00 00 00 00 02 10 14 39 00 00 00 00 00 02 11 14 39 00 00 00 00 00 02 12 13 39 00 00 00 00 00 02 13 12 39 00 00 00 00 00 02 14 11 39 00 00 00 00 00 02 15 10 39 00 00 00 00 00 02 16 0f 39 00 00 00 00 00 02 17 0e 39 00 00 00 00 00 02 18 0d 39 00 00 00 00 00 02 19 0c 39 00 00 00 00 00 02 22 ff 39 00 00 00 00 00 02 43 ff 39 00 00 00 00 00 02 44 00 39 00 00 00 00 00 02 45 11 39 00 00 00 00 00 02 46 11 39 00 00 00 00 00 02 47 42 39 00 00 00 00 00 02 48 f7 39 00 00 00 00 00 02 49 ff 39 00 00 00 00 00 02 4a 1f 39 00 00 00 00 00 02 4b 1f 39 00 00 00 00 00 02 4c 1f 39 00 00 00 00 00 02 4d 1f 39 00 00 00 00 00 02 4e bc 39 00 00 00 00 00 02 4f 5e 39 00 00 00 00 00 02 50 9e 39 00 00 00 00 00 02 51 ff 39 00 00 00 00 00 02 52 ff 39 00 00 00 00 00 02 53 ff 39 00 00 00 00 00 02 61 ff 39 00 00 00 00 00 02 fe 20 39 00 00 00 00 00 02 ba 05 39 00 00 00 00 00 02 5d 02 39 00 00 00 00 00 02 75 3f 39 00 00 00 00 00 02 76 3f 39 00 00 00 00 00 02 77 3f 39 00 00 00 00 00 02 78 5a 39 00 00 00 00 00 02 7a 5a 39 00 00 00 00 00 02 7b 67 39 00 00 00 00 00 02 7c 70 39 00 00 00 00 00 02 7d 77 39 01 00 00 00 00 02 fe 00];
				mi,mdss-dsi-dc-off-command-state = "dsi_lp_mode";
				mi,mdss-dsi-nolp-command = [39 00 00 00 00 00 02 fe 00 15 00 00 00 00 00 02 38 00 39 00 00 00 00 00 02 fe 60 39 00 00 00 00 00 02 c3 08 39 01 00 00 00 00 02 fe 00];
				mi,mdss-dsi-nolp-command-state = "dsi_lp_mode";
				qcom,mdss-dsi-panel-phy-timings = [00 1d 07 07 17 22 07 07 08 02 04 00 19 0c];
				qcom,display-topology = <0x1 0x1 0x1>;
				qcom,default-topology-index = <0x0>;
			};

			timing@1 {
				qcom,mdss-dsi-panel-framerate = <0x5a>;
				qcom,mdss-dsi-panel-width = <0x348>;
				qcom,mdss-dsi-panel-height = <0x9d8>;
				qcom,mdss-dsi-h-front-porch = <0x1c>;
				qcom,mdss-dsi-h-back-porch = <0x24>;
				qcom,mdss-dsi-h-pulse-width = <0x4>;
				qcom,mdss-dsi-h-sync-skew = <0x0>;
				qcom,mdss-dsi-v-back-porch = <0x14>;
				qcom,mdss-dsi-v-front-porch = <0x10>;
				qcom,mdss-dsi-v-pulse-width = <0x4>;
				qcom,mdss-dsi-h-sync-pulse = <0x0>;
				qcom,mdss-dsi-h-left-border = <0x0>;
				qcom,mdss-dsi-h-right-border = <0x0>;
				qcom,mdss-dsi-v-top-border = <0x0>;
				qcom,mdss-dsi-v-bottom-border = <0x0>;
				qcom,mdss-dsi-panel-clockrate = <0x26be3680>;
				qcom,mdss-dsi-panel-jitter = <0x5 0x1>;
				qcom,mdss-dsi-on-command = <0x39000000 0x2fe 0x390000 0x2 0xfa013900 0x0 0x2fee039 0x0 0x2e700 0x39000000 0x2fe 0x390000 0x2 0x5e013900 0x0 0x2c20839 0x0 0x23500 0x39010000 0x351 0x7ff0501 0x7800 0x2110005 0x100001e 0x22900>;
				qcom,mdss-dsi-off-command = [05 01 00 00 14 00 02 28 00 05 01 00 00 78 00 02 10 00];
				qcom,mdss-dsi-on-command-state = "dsi_lp_mode";
				qcom,mdss-dsi-off-command-state = "dsi_lp_mode";
				qcom,mdss-dsi-timing-switch-command = <0x39000000 0x2fe 0xd0390000 0x2 0x70013900 0x0 0x2fe7439 0x0 0x20eff 0x39000000 0x20f 0x390000 0x2 0x10093900 0x0 0x2110939 0x0 0x21208 0x39000000 0x213 0x7390000 0x2 0x14063900 0x0 0x2150539 0x0 0x21604 0x39000000 0x217 0x3390000 0x2 0x18023900 0x0 0x2190139 0x1000000 0x2fe00>;
				qcom,mdss-dsi-timing-switch-command-state = "dsi_lp_mode";
				qcom,mdss-dsi-lp1-command = [39 00 00 00 00 00 02 fe d0 39 00 00 00 00 00 02 70 81 39 00 00 00 00 00 02 fe 60 39 00 00 00 00 00 02 c3 00 39 00 00 00 00 00 02 fe 74 39 00 00 00 00 00 02 0e ff 39 00 00 00 00 00 02 0f 00 39 00 00 00 00 00 02 10 14 39 00 00 00 00 00 02 11 14 39 00 00 00 00 00 02 12 13 39 00 00 00 00 00 02 13 12 39 00 00 00 00 00 02 14 11 39 00 00 00 00 00 02 15 10 39 00 00 00 00 00 02 16 0f 39 00 00 00 00 00 02 17 0e 39 00 00 00 00 00 02 18 0d 39 00 00 00 00 00 02 19 0c 39 00 00 00 00 00 02 fe 00 15 01 00 00 00 00 02 39 00];
				qcom,mdss-dsi-lp1-command-state = "dsi_lp_mode";
				qcom,mdss-dsi-nolp-command = <0x39000000 0x2fe 0x150000 0x2 0x38003900 0x0 0x2fed039 0x0 0x27001 0x39000000 0x2fe 0x60390000 0x2 0xc3083900 0x0 0x2fe7439 0x0 0x20eff 0x39000000 0x20f 0x390000 0x2 0x10093900 0x0 0x2110939 0x0 0x21208 0x39000000 0x213 0x7390000 0x2 0x14063900 0x0 0x2150539 0x0 0x21604 0x39000000 0x217 0x3390000 0x2 0x18023900 0x0 0x2190139 0x1000000 0x2fe00>;
				qcom,mdss-dsi-nolp-command-state = "dsi_lp_mode";
				qcom,compression-mode = "dsc";
				qcom,mdss-dsc-slice-height = <0x1a4>;
				qcom,mdss-dsc-slice-width = <0x348>;
				qcom,mdss-dsc-slice-per-pkt = <0x2>;
				qcom,mdss-dsc-bit-per-component = <0x8>;
				qcom,mdss-dsc-bit-per-pixel = <0x8>;
				qcom,mdss-dsc-block-prediction-enable;
				mi,mdss-dsi-timing-switch-command = <0x39000000 0x2fe 0xd0390000 0x2 0x70013900 0x0 0x2fe7439 0x0 0x20eff 0x39000000 0x20f 0x390000 0x2 0x10093900 0x0 0x2110939 0x0 0x21208 0x39000000 0x213 0x7390000 0x2 0x14063900 0x0 0x2150539 0x0 0x21604 0x39000000 0x217 0x3390000 0x2 0x18023900 0x0 0x2190139 0x1000000 0x2fe00>;
				mi,mdss-dsi-timing-switch-command-state = "dsi_lp_mode";
				mi,mdss-dsi-timing-switch-dc-lbm-command = [39 00 00 00 00 00 02 fe 60 39 00 00 00 00 00 02 c3 08 39 00 00 00 00 00 02 fe 74 39 00 00 00 00 00 02 00 00 39 00 00 00 00 00 02 01 00 39 00 00 00 00 00 02 02 11 39 00 00 00 00 00 02 03 73 39 00 00 00 00 00 02 04 0f 39 00 00 00 00 00 02 05 0a 39 00 00 00 00 00 02 06 26 39 00 00 00 00 00 02 07 5f 39 00 00 00 00 00 02 08 be 39 00 00 00 00 00 02 09 1d 39 00 00 00 00 00 02 0a dc 39 00 00 00 00 00 02 0b b8 39 00 00 00 00 00 02 0c ff 39 00 00 00 00 00 02 0d ff 39 00 00 00 00 00 02 0e ff 39 00 00 00 00 00 02 0f 00 39 00 00 00 00 00 02 10 14 39 00 00 00 00 00 02 11 14 39 00 00 00 00 00 02 12 13 39 00 00 00 00 00 02 13 12 39 00 00 00 00 00 02 14 11 39 00 00 00 00 00 02 15 10 39 00 00 00 00 00 02 16 0f 39 00 00 00 00 00 02 17 0e 39 00 00 00 00 00 02 18 0d 39 00 00 00 00 00 02 19 0c 39 00 00 00 00 00 02 22 ff 39 00 00 00 00 00 02 43 ff 39 00 00 00 00 00 02 44 00 39 00 00 00 00 00 02 45 11 39 00 00 00 00 00 02 46 11 39 00 00 00 00 00 02 47 42 39 00 00 00 00 00 02 48 f7 39 00 00 00 00 00 02 49 ff 39 00 00 00 00 00 02 4a 1f 39 00 00 00 00 00 02 4b 1f 39 00 00 00 00 00 02 4c 1f 39 00 00 00 00 00 02 4d 1f 39 00 00 00 00 00 02 4e bc 39 00 00 00 00 00 02 4f 5e 39 00 00 00 00 00 02 50 9e 39 00 00 00 00 00 02 51 ff 39 00 00 00 00 00 02 52 ff 39 00 00 00 00 00 02 53 ff 39 00 00 00 00 00 02 61 ff 39 00 00 00 00 00 02 fe 20 39 00 00 00 00 00 02 ba 05 39 00 00 00 00 00 02 5d 02 39 00 00 00 00 00 02 75 3f 39 00 00 00 00 00 02 76 3f 39 00 00 00 00 00 02 77 3f 39 00 00 00 00 00 02 78 5a 39 00 00 00 00 00 02 7a 5a 39 00 00 00 00 00 02 7b 67 39 00 00 00 00 00 02 7c 70 39 01 00 00 00 00 02 7d 77 39 00 00 00 00 00 02 fe d0 39 00 00 00 00 00 02 70 01 39 00 00 00 00 00 02 fe 74 39 00 00 00 00 00 02 0e ff 39 00 00 00 00 00 02 0f 00 39 00 00 00 00 00 02 10 09 39 00 00 00 00 00 02 11 09 39 00 00 00 00 00 02 12 08 39 00 00 00 00 00 02 13 07 39 00 00 00 00 00 02 14 06 39 00 00 00 00 00 02 15 05 39 00 00 00 00 00 02 16 04 39 00 00 00 00 00 02 17 03 39 00 00 00 00 00 02 18 02 39 01 00 00 00 00 02 19 01 39 00 00 00 00 00 02 fe 60 39 00 00 00 00 00 02 c3 08 39 00 00 00 00 00 02 fe 74 39 00 00 00 00 00 02 00 00 39 00 00 00 00 00 02 01 00 39 00 00 00 00 00 02 02 00 39 00 00 00 00 00 02 03 70 39 00 00 00 00 00 02 04 0f 39 00 00 00 00 00 02 05 00 39 00 00 00 00 00 02 06 00 39 00 00 00 00 00 02 07 00 39 00 00 00 00 00 02 08 00 39 00 00 00 00 00 02 09 00 39 00 00 00 00 00 02 0a 00 39 00 00 00 00 00 02 0b 00 39 00 00 00 00 00 02 0c ff 39 00 00 00 00 00 02 0d ff 39 00 00 00 00 00 02 0e 80 39 00 00 00 00 00 02 0f 00 39 00 00 00 00 00 02 10 02 39 00 00 00 00 00 02 11 00 39 00 00 00 00 00 02 12 00 39 00 00 00 00 00 02 13 00 39 00 00 00 00 00 02 14 00 39 00 00 00 00 00 02 15 00 39 00 00 00 00 00 02 16 00 39 00 00 00 00 00 02 17 00 39 00 00 00 00 00 02 18 02 39 00 00 00 00 00 02 19 01 39 00 00 00 00 00 02 22 80 39 00 00 00 00 00 02 43 80 39 00 00 00 00 00 02 44 00 39 00 00 00 00 00 02 45 ff 39 00 00 00 00 00 02 46 ff 39 00 00 00 00 00 02 47 ff 39 00 00 00 00 00 02 48 ff 39 00 00 00 00 00 02 49 ff 39 00 00 00 00 00 02 4a ff 39 00 00 00 00 00 02 4b ff 39 00 00 00 00 00 02 4c ff 39 00 00 00 00 00 02 4d ff 39 00 00 00 00 00 02 4e ff 39 00 00 00 00 00 02 4f ff 39 00 00 00 00 00 02 50 ff 39 00 00 00 00 00 02 51 ff 39 00 00 00 00 00 02 52 ff 39 00 00 00 00 00 02 53 ff 39 00 00 00 00 00 02 61 80 39 00 00 00 00 00 02 fe 20 39 00 00 00 00 00 02 ba 03 39 00 00 00 00 00 02 5d 02 39 00 00 00 00 00 02 75 7f 39 00 00 00 00 00 02 76 7f 39 00 00 00 00 00 02 77 7f 39 00 00 00 00 00 02 78 7f 39 00 00 00 00 00 02 7a 7f 39 00 00 00 00 00 02 7b 7f 39 00 00 00 00 00 02 7c 7f 39 00 00 00 00 00 02 7d 7f 39 01 00 00 00 00 02 fe 00];
				mi,mdss-dsi-timing-switch-dc-lbm-command-state = "dsi_lp_mode";
				mi,mdss-dsi-timing-switch-dc-hbm-command = [39 00 00 00 00 00 02 fe 60 39 00 00 00 00 00 02 c3 00 39 00 00 00 00 00 02 fe 74 39 00 00 00 00 00 02 00 00 39 00 00 00 00 00 02 01 00 39 00 00 00 00 00 02 02 11 39 00 00 00 00 00 02 03 73 39 00 00 00 00 00 02 04 0f 39 00 00 00 00 00 02 05 0a 39 00 00 00 00 00 02 06 26 39 00 00 00 00 00 02 07 5f 39 00 00 00 00 00 02 08 be 39 00 00 00 00 00 02 09 1d 39 00 00 00 00 00 02 0a dc 39 00 00 00 00 00 02 0b b8 39 00 00 00 00 00 02 0c ff 39 00 00 00 00 00 02 0d ff 39 00 00 00 00 00 02 0e ff 39 00 00 00 00 00 02 0f 00 39 00 00 00 00 00 02 10 14 39 00 00 00 00 00 02 11 14 39 00 00 00 00 00 02 12 13 39 00 00 00 00 00 02 13 12 39 00 00 00 00 00 02 14 11 39 00 00 00 00 00 02 15 10 39 00 00 00 00 00 02 16 0f 39 00 00 00 00 00 02 17 0e 39 00 00 00 00 00 02 18 0d 39 00 00 00 00 00 02 19 0c 39 00 00 00 00 00 02 22 ff 39 00 00 00 00 00 02 43 ff 39 00 00 00 00 00 02 44 00 39 00 00 00 00 00 02 45 11 39 00 00 00 00 00 02 46 11 39 00 00 00 00 00 02 47 42 39 00 00 00 00 00 02 48 f7 39 00 00 00 00 00 02 49 ff 39 00 00 00 00 00 02 4a 1f 39 00 00 00 00 00 02 4b 1f 39 00 00 00 00 00 02 4c 1f 39 00 00 00 00 00 02 4d 1f 39 00 00 00 00 00 02 4e bc 39 00 00 00 00 00 02 4f 5e 39 00 00 00 00 00 02 50 9e 39 00 00 00 00 00 02 51 ff 39 00 00 00 00 00 02 52 ff 39 00 00 00 00 00 02 53 ff 39 00 00 00 00 00 02 61 ff 39 00 00 00 00 00 02 fe 20 39 00 00 00 00 00 02 ba 05 39 00 00 00 00 00 02 5d 02 39 00 00 00 00 00 02 75 3f 39 00 00 00 00 00 02 76 3f 39 00 00 00 00 00 02 77 3f 39 00 00 00 00 00 02 78 5a 39 00 00 00 00 00 02 7a 5a 39 00 00 00 00 00 02 7b 67 39 00 00 00 00 00 02 7c 70 39 01 00 00 00 00 02 7d 77 39 00 00 00 00 00 02 fe d0 39 00 00 00 00 00 02 70 01 39 00 00 00 00 00 02 fe 74 39 00 00 00 00 00 02 0e ff 39 00 00 00 00 00 02 0f 00 39 00 00 00 00 00 02 10 09 39 00 00 00 00 00 02 11 09 39 00 00 00 00 00 02 12 08 39 00 00 00 00 00 02 13 07 39 00 00 00 00 00 02 14 06 39 00 00 00 00 00 02 15 05 39 00 00 00 00 00 02 16 04 39 00 00 00 00 00 02 17 03 39 00 00 00 00 00 02 18 02 39 01 00 00 00 00 02 19 01 39 00 00 00 00 00 02 fe 60 39 00 00 00 00 00 02 c3 08 39 00 00 00 00 00 02 fe 74 39 00 00 00 00 00 02 00 00 39 00 00 00 00 00 02 01 00 39 00 00 00 00 00 02 02 00 39 00 00 00 00 00 02 03 70 39 00 00 00 00 00 02 04 0f 39 00 00 00 00 00 02 05 00 39 00 00 00 00 00 02 06 00 39 00 00 00 00 00 02 07 00 39 00 00 00 00 00 02 08 00 39 00 00 00 00 00 02 09 00 39 00 00 00 00 00 02 0a 00 39 00 00 00 00 00 02 0b 00 39 00 00 00 00 00 02 0c ff 39 00 00 00 00 00 02 0d ff 39 00 00 00 00 00 02 0e 80 39 00 00 00 00 00 02 0f 00 39 00 00 00 00 00 02 10 02 39 00 00 00 00 00 02 11 00 39 00 00 00 00 00 02 12 00 39 00 00 00 00 00 02 13 00 39 00 00 00 00 00 02 14 00 39 00 00 00 00 00 02 15 00 39 00 00 00 00 00 02 16 00 39 00 00 00 00 00 02 17 00 39 00 00 00 00 00 02 18 02 39 00 00 00 00 00 02 19 01 39 00 00 00 00 00 02 22 80 39 00 00 00 00 00 02 43 80 39 00 00 00 00 00 02 44 00 39 00 00 00 00 00 02 45 ff 39 00 00 00 00 00 02 46 ff 39 00 00 00 00 00 02 47 ff 39 00 00 00 00 00 02 48 ff 39 00 00 00 00 00 02 49 ff 39 00 00 00 00 00 02 4a ff 39 00 00 00 00 00 02 4b ff 39 00 00 00 00 00 02 4c ff 39 00 00 00 00 00 02 4d ff 39 00 00 00 00 00 02 4e ff 39 00 00 00 00 00 02 4f ff 39 00 00 00 00 00 02 50 ff 39 00 00 00 00 00 02 51 ff 39 00 00 00 00 00 02 52 ff 39 00 00 00 00 00 02 53 ff 39 00 00 00 00 00 02 61 80 39 00 00 00 00 00 02 fe 20 39 00 00 00 00 00 02 ba 03 39 00 00 00 00 00 02 5d 02 39 00 00 00 00 00 02 75 7f 39 00 00 00 00 00 02 76 7f 39 00 00 00 00 00 02 77 7f 39 00 00 00 00 00 02 78 7f 39 00 00 00 00 00 02 7a 7f 39 00 00 00 00 00 02 7b 7f 39 00 00 00 00 00 02 7c 7f 39 00 00 00 00 00 02 7d 7f 39 01 00 00 00 00 02 fe 00];
				mi,mdss-dsi-timing-switch-dc-hbm-command-state = "dsi_lp_mode";
				mi,mdss-dsi-dc-on-command = <0x39000000 0x2fe 0x60390000 0x2 0xc3083900 0x0 0x2fe7439 0x0 0x20000 0x39000000 0x201 0x390000 0x2 0x2003900 0x0 0x2037039 0x0 0x2040f 0x39000000 0x205 0x390000 0x2 0x6003900 0x0 0x2070039 0x0 0x20800 0x39000000 0x209 0x390000 0x2 0xa003900 0x0 0x20b0039 0x0 0x20cff 0x39000000 0x20d 0xff390000 0x2 0xe803900 0x0 0x20f0039 0x0 0x21002 0x39000000 0x211 0x390000 0x2 0x12003900 0x0 0x2130039 0x0 0x21400 0x39000000 0x215 0x390000 0x2 0x16003900 0x0 0x2170039 0x0 0x21802 0x39000000 0x219 0x1390000 0x2 0x22803900 0x0 0x2438039 0x0 0x24400 0x39000000 0x245 0xff390000 0x2 0x46ff3900 0x0 0x247ff39 0x0 0x248ff 0x39000000 0x249 0xff390000 0x2 0x4aff3900 0x0 0x24bff39 0x0 0x24cff 0x39000000 0x24d 0xff390000 0x2 0x4eff3900 0x0 0x24fff39 0x0 0x250ff 0x39000000 0x251 0xff390000 0x2 0x52ff3900 0x0 0x253ff39 0x0 0x26180 0x39000000 0x2fe 0x20390000 0x2 0xba033900 0x0 0x25d0239 0x0 0x2757f 0x39000000 0x276 0x7f390000 0x2 0x777f3900 0x0 0x2787f39 0x0 0x27a7f 0x39000000 0x27b 0x7f390000 0x2 0x7c7f3900 0x0 0x27d7f39 0x1000000 0x2fe00>;
				mi,mdss-dsi-dc-on-command-state = "dsi_lp_mode";
				mi,mdss-dsi-dc-off-command = <0x39000000 0x2fe 0x60390000 0x2 0xc3083900 0x0 0x2fe7439 0x0 0x20000 0x39000000 0x201 0x390000 0x2 0x2113900 0x0 0x2037339 0x0 0x2040f 0x39000000 0x205 0xa390000 0x2 0x6263900 0x0 0x2075f39 0x0 0x208be 0x39000000 0x209 0x1d390000 0x2 0xadc3900 0x0 0x20bb839 0x0 0x20cff 0x39000000 0x20d 0xff390000 0x2 0xeff3900 0x0 0x20f0039 0x0 0x21009 0x39000000 0x211 0x9390000 0x2 0x12083900 0x0 0x2130739 0x0 0x21406 0x39000000 0x215 0x5390000 0x2 0x16043900 0x0 0x2170339 0x0 0x21802 0x39000000 0x219 0x1390000 0x2 0x22ff3900 0x0 0x243ff39 0x0 0x24400 0x39000000 0x245 0x11390000 0x2 0x46113900 0x0 0x2474239 0x0 0x248f7 0x39000000 0x249 0xff390000 0x2 0x4a1f3900 0x0 0x24b1f39 0x0 0x24c1f 0x39000000 0x24d 0x1f390000 0x2 0x4ebc3900 0x0 0x24f5e39 0x0 0x2509e 0x39000000 0x251 0xff390000 0x2 0x52ff3900 0x0 0x253ff39 0x0 0x261ff 0x39000000 0x2fe 0x20390000 0x2 0xba053900 0x0 0x25d0239 0x0 0x2753f 0x39000000 0x276 0x3f390000 0x2 0x773f3900 0x0 0x2785a39 0x0 0x27a5a 0x39000000 0x27b 0x67390000 0x2 0x7c703900 0x0 0x27d7739 0x1000000 0x2fe00>;
				mi,mdss-dsi-dc-off-command-state = "dsi_lp_mode";
				mi,mdss-dsi-nolp-command = <0x39000000 0x2fe 0x150000 0x2 0x38003900 0x0 0x2fed039 0x0 0x27001 0x39000000 0x2fe 0x60390000 0x2 0xc3083900 0x0 0x2fe7439 0x0 0x20eff 0x39000000 0x20f 0x390000 0x2 0x10093900 0x0 0x2110939 0x0 0x21208 0x39000000 0x213 0x7390000 0x2 0x14063900 0x0 0x2150539 0x0 0x21604 0x39000000 0x217 0x3390000 0x2 0x18023900 0x0 0x2190139 0x1000000 0x2fe00>;
				mi,mdss-dsi-nolp-command-state = "dsi_lp_mode";
				qcom,mdss-dsi-panel-phy-timings = [00 1d 07 07 17 22 07 07 08 02 04 00 19 0c];
				qcom,display-topology = <0x1 0x1 0x1>;
				qcom,default-topology-index = <0x0>;
			};
		};
	};

	qcom,mdss_dsi_k11_38_08_0a_dsc_cmd {
		qcom,mdss-dsi-panel-name = "xiaomi 38 08 0a cmd mode dsc dsi panel";
		qcom,mdss-dsi-panel-type = "dsi_cmd_mode";
		qcom,mdss-dsi-virtual-channel-id = <0x0>;
		qcom,mdss-dsi-stream = <0x0>;
		qcom,mdss-dsi-bpp = <0x18>;
		qcom,mdss-dsi-color-order = "rgb_swap_rgb";
		qcom,mdss-dsi-underflow-color = <0xff>;
		qcom,mdss-dsi-border-color = <0x0>;
		qcom,dsi-ctrl-num = <0x0>;
		qcom,dsi-phy-num = <0x0>;
		qcom,mdss-dsi-traffic-mode = "burst_mode";
		qcom,mdss-dsi-lane-map = "lane_map_0123";
		qcom,mdss-dsi-bllp-eof-power-mode;
		qcom,mdss-dsi-bllp-power-mode;
		qcom,mdss-dsi-lane-0-state;
		qcom,mdss-dsi-lane-1-state;
		qcom,mdss-dsi-lane-2-state;
		qcom,mdss-dsi-lane-3-state;
		qcom,mdss-dsi-dma-trigger = "trigger_sw";
		qcom,mdss-dsi-mdp-trigger = "none";
		qcom,mdss-dsi-reset-sequence = <0x0 0xa 0x1 0xa>;
		qcom,mdss-pan-physical-width-dimension = <0x47>;
		qcom,mdss-pan-physical-height-dimension = <0x99>;
		qcom,mdss-dsi-te-pin-select = <0x1>;
		qcom,mdss-dsi-wr-mem-start = <0x2c>;
		qcom,mdss-dsi-wr-mem-continue = <0x3c>;
		qcom,mdss-dsi-te-dcs-command = <0x1>;
		qcom,mdss-dsi-te-check-enable;
		qcom,mdss-dsi-te-using-te-pin;
		qcom,mdss-dsi-tx-eot-append;
		qcom,mdss-dsi-lp11-init;
		qcom,mdss-dsi-panel-mode-switch;
		qcom,mdss-dsi-bl-inverted-dbv;
		qcom,bl-update-flag = "delay_until_first_frame";
		mi,panel-id = "", "K11", "8\b";
		mi,hbm-51-ctl-flag;
		mi,hbm-off-51-index = <0x1>;
		mi,hbm-on-51-index = <0x1>;
		mi,hbm-bl-min-level = <0x1>;
		mi,hbm-bl-max-level = <0x7ff>;
		mi,esd-err-irq-gpio = <0xffffffff 0x4b 0x2001>;
		mi,panel-on-dimming-delay = <0x78>;
		mi,mdss-dsi-panel-dc-threshold = <0x1b8>;
		qcom,dsi-select-clocks = "mux_byte_clk0", "mux_pixel_clk0";
		qcom,panel-supply-entries = <0x21>;
		qcom,mdss-dsi-bl-pmic-control-type = "bl_ctrl_dcs";
		qcom,mdss-dsi-bl-min-level = <0x2>;
		qcom,mdss-dsi-bl-max-level = <0x7ff>;
		qcom,mdss-brightness-max-level = <0x7ff>;
		qcom,platform-te-gpio = <0xffffffff 0x52 0x0>;
		qcom,platform-reset-gpio = <0xffffffff 0x18 0x0>;

		qcom,mdss-dsi-display-timings {

			timing@0 {
				qcom,mdss-dsi-cmd-mode;
				qcom,mdss-dsi-panel-framerate = <0x78>;
				qcom,mdss-dsi-panel-width = <0x438>;
				qcom,mdss-dsi-panel-height = <0x960>;
				qcom,mdss-dsi-h-front-porch = <0x10>;
				qcom,mdss-dsi-h-back-porch = <0x8>;
				qcom,mdss-dsi-h-pulse-width = <0x8>;
				qcom,mdss-dsi-h-sync-skew = <0x0>;
				qcom,mdss-dsi-v-back-porch = <0x8>;
				qcom,mdss-dsi-v-front-porch = <0x4>;
				qcom,mdss-dsi-v-pulse-width = <0x4>;
				qcom,mdss-dsi-h-sync-pulse = <0x0>;
				qcom,mdss-dsi-h-left-border = <0x0>;
				qcom,mdss-dsi-h-right-border = <0x0>;
				qcom,mdss-dsi-v-top-border = <0x0>;
				qcom,mdss-dsi-v-bottom-border = <0x0>;
				qcom,mdss-dsi-panel-clockrate = <0x4190ab00>;
				qcom,mdss-dsi-panel-jitter = <0x5 0x1>;
				qcom,mdss-mdp-transfer-time-us = <0x1b58>;
				qcom,mdss-dsi-on-command = [15 01 00 00 00 00 02 9d 01 39 01 00 00 0a 00 81 9e 11 00 00 89 30 80 09 60 04 38 00 08 02 1c 02 1c 02 00 02 0e 00 20 00 bb 00 07 00 0c 0d b7 0c b7 18 00 10 f0 03 0c 20 00 06 0b 0b 33 0e 1c 2a 38 46 54 62 69 70 77 79 7b 7d 7e 01 02 01 00 09 40 09 be 19 fc 19 fa 19 f8 1a 38 1a 78 1a b6 2a f6 2b 34 2b 74 3b 74 6b f4 00 00 00 00 00 00 00 00 00 00 00 00 00 00 00 00 00 00 00 00 00 00 00 00 00 00 00 00 00 00 00 00 00 00 00 00 00 00 00 00 05 01 00 00 0a 00 02 11 00 15 01 00 00 00 00 02 35 00 39 01 00 00 00 00 05 2a 00 00 04 37 39 01 00 00 00 00 05 2b 00 00 09 5f 39 01 00 00 00 00 03 f0 5a 5a 15 01 00 00 00 00 02 b0 01 15 01 00 00 00 00 02 b7 4f 39 01 00 00 00 00 03 f0 a5 a5 39 01 00 00 00 00 03 f0 5a 5a 15 01 00 00 00 00 02 b0 02 39 01 00 00 00 00 05 ec 00 c0 c3 43 15 01 00 00 00 00 02 b0 0d 15 01 00 00 00 00 02 ec 19 15 01 00 00 00 00 02 b0 06 15 01 00 00 00 00 02 e4 d0 39 01 00 00 00 00 03 f0 a5 a5 39 01 00 00 00 00 03 f0 5a 5a 15 01 00 00 00 00 02 b0 36 15 01 00 00 00 00 02 d3 0f 15 01 00 00 00 00 02 f7 03 39 01 00 00 00 00 03 f0 a5 a5 39 01 00 00 00 00 03 f0 5a 5a 39 01 00 00 00 00 03 fc 5a 5a 15 01 00 00 00 00 02 b0 01 39 01 00 00 00 00 04 e4 a6 75 a3 39 01 00 00 00 00 0f e9 11 75 a6 75 a3 8d 06 20 8c a2 4e 00 32 32 39 01 00 00 00 00 03 fc a5 a5 39 01 00 00 00 00 03 f0 a5 a5 39 01 00 00 00 00 03 f0 5a 5a 39 01 00 00 00 00 04 df 83 00 10 15 01 00 00 00 00 02 b0 01 15 01 00 00 00 00 02 e6 01 39 01 00 00 00 00 03 f0 a5 a5 39 01 00 00 00 00 03 f0 5a 5a 39 01 00 00 00 00 03 fc 5a 5a 15 01 00 00 00 00 02 b0 16 15 01 00 00 00 00 02 d1 2e 39 01 00 00 00 00 03 fc a5 a5 39 01 00 00 5a 00 03 f0 a5 a5 39 01 00 00 00 00 03 f0 5a 5a 15 01 00 00 00 00 02 b0 06 15 01 00 00 00 00 02 b7 20 15 01 00 00 00 00 02 b0 05 15 01 00 00 00 00 02 b7 93 39 01 00 00 00 00 03 f0 a5 a5 15 01 00 00 00 00 02 53 20 39 01 00 00 00 00 03 51 00 00 05 01 00 00 00 00 02 29 00 15 01 00 00 00 00 02 60 10];
				qcom,mdss-dsi-off-command = [05 01 00 00 14 00 02 28 00 15 01 00 00 00 00 02 53 20 05 01 00 00 78 00 02 10 00];
				qcom,mdss-dsi-on-command-state = "dsi_lp_mode";
				qcom,mdss-dsi-off-command-state = "dsi_lp_mode";
				qcom,mdss-dsi-timing-switch-command = [15 01 00 00 00 00 02 60 10];
				qcom,mdss-dsi-timing-switch-command-state = "dsi_lp_mode";
				qcom,mdss-dsi-nolp-command = [39 01 00 00 00 00 03 f0 5a 5a 15 00 00 00 00 00 02 b0 0a 15 00 00 00 00 00 02 ee 06 15 00 00 00 00 00 02 b0 0b 39 00 00 00 00 00 03 d8 59 70 15 00 00 00 00 00 02 60 10 15 01 00 00 00 00 02 53 28 39 01 00 00 09 00 03 f0 a5 a5];
				qcom,mdss-dsi-nolp-command-state = "dsi_lp_mode";
				qcom,compression-mode = "dsc";
				qcom,mdss-dsc-slice-height = <0x8>;
				qcom,mdss-dsc-slice-width = <0x21c>;
				qcom,mdss-dsc-slice-per-pkt = <0x2>;
				qcom,mdss-dsc-bit-per-component = <0x8>;
				qcom,mdss-dsc-bit-per-pixel = <0x8>;
				qcom,mdss-dsc-block-prediction-enable;
				mi,mdss-dsi-dimmingon-command = [15 01 00 00 00 00 02 53 28];
				mi,mdss-dsi-dimmingon-command-state = "dsi_hs_mode";
				mi,mdss-dsi-dimmingoff-command = [15 01 00 00 00 00 02 53 20];
				mi,mdss-dsi-dimmingoff-command-state = "dsi_hs_mode";
				mi,mdss-dsi-hbm-on-command = [15 01 00 00 00 00 02 53 e8 39 01 00 00 00 00 03 51 07 ff];
				mi,mdss-dsi-hbm-off-command = [15 01 00 00 00 00 02 53 28 39 01 00 00 00 00 03 51 07 ff];
				mi,mdss-dsi-hbm-on-command-state = "dsi_lp_mode";
				mi,mdss-dsi-hbm-off-command-state = "dsi_lp_mode";
				mi,mdss-dsi-doze-hbm-command = [39 01 00 00 00 00 03 f0 5a 5a 15 00 00 00 00 00 02 60 00 15 00 00 00 00 00 02 b0 0b 39 00 00 00 00 00 03 d8 50 00 15 01 00 00 00 00 02 53 22 39 01 00 00 00 00 03 f0 5a 5a];
				mi,mdss-dsi-doze-lbm-command = [39 01 00 00 00 00 03 f0 5a 5a 15 00 00 00 00 00 02 60 00 15 00 00 00 00 00 02 b0 0b 39 00 00 00 00 00 03 d8 50 00 15 01 00 00 00 00 02 53 23 39 01 00 00 00 00 03 f0 5a 5a];
				mi,mdss-dsi-doze-hbm-command-state = "dsi_lp_mode";
				mi,mdss-dsi-doze-lbm-command-state = "dsi_lp_mode";
				mi,mdss-dsi-flat-mode-on-command = [39 01 00 00 00 00 03 f0 5a 5a 39 00 00 00 00 00 1d c2 2d 27 fe 82 c6 70 82 70 ca 0a 0a 0a 28 28 28 35 35 35 3f 3f 3f 42 42 42 1b da 2f 48 15 01 00 00 00 00 02 f7 03 39 01 00 00 09 00 03 f0 a5 a5];
				mi,mdss-dsi-flat-mode-off-command = [39 01 00 00 00 00 03 f0 5a 5a 39 00 00 00 00 00 1d c2 2d 07 fe 82 c6 70 82 70 ca 0a 0a 0a 28 28 28 35 35 35 3f 3f 3f 42 42 42 1b da 2f 48 15 01 00 00 00 00 02 f7 03 39 01 00 00 09 00 03 f0 a5 a5];
				mi,mdss-dsi-flat-mode-on-command-state = "dsi_lp_mode";
				mi,mdss-dsi-flat-mode-off-command-state = "dsi_lp_mode";
				mi,mdss-dsi-crc-off-command = [39 01 00 00 00 00 02 81 00 39 00 00 00 00 00 03 f0 5a 5a 39 00 00 00 00 00 02 b1 01 39 01 00 00 00 00 03 f0 a5 a5];
				mi,mdss-dsi-crc-off-command-state = "dsi_hs_mode";
				qcom,mdss-dsi-panel-phy-timings = [00 24 0a 0a 1a 19 09 0a 09 02 04 00 1e 0f];
				qcom,display-topology = <0x1 0x1 0x1>;
				qcom,default-topology-index = <0x0>;
			};

			timing@1 {
				qcom,mdss-dsi-cmd-mode;
				qcom,mdss-dsi-panel-framerate = <0x3c>;
				qcom,mdss-dsi-panel-width = <0x438>;
				qcom,mdss-dsi-panel-height = <0x960>;
				qcom,mdss-dsi-h-front-porch = <0x10>;
				qcom,mdss-dsi-h-back-porch = <0x8>;
				qcom,mdss-dsi-h-pulse-width = <0x8>;
				qcom,mdss-dsi-h-sync-skew = <0x0>;
				qcom,mdss-dsi-v-back-porch = <0x230>;
				qcom,mdss-dsi-v-front-porch = <0x258>;
				qcom,mdss-dsi-v-pulse-width = <0x20>;
				qcom,mdss-dsi-h-sync-pulse = <0x0>;
				qcom,mdss-dsi-h-left-border = <0x0>;
				qcom,mdss-dsi-h-right-border = <0x0>;
				qcom,mdss-dsi-v-top-border = <0x0>;
				qcom,mdss-dsi-v-bottom-border = <0x0>;
				qcom,mdss-dsi-panel-clockrate = <0x4190ab00>;
				qcom,mdss-dsi-panel-jitter = <0x5 0x1>;
				qcom,mdss-mdp-transfer-time-us = <0x1b58>;
				qcom,mdss-dsi-on-command = [15 01 00 00 00 00 02 9d 01 39 01 00 00 0a 00 81 9e 11 00 00 89 30 80 09 60 04 38 00 08 02 1c 02 1c 02 00 02 0e 00 20 00 bb 00 07 00 0c 0d b7 0c b7 18 00 10 f0 03 0c 20 00 06 0b 0b 33 0e 1c 2a 38 46 54 62 69 70 77 79 7b 7d 7e 01 02 01 00 09 40 09 be 19 fc 19 fa 19 f8 1a 38 1a 78 1a b6 2a f6 2b 34 2b 74 3b 74 6b f4 00 00 00 00 00 00 00 00 00 00 00 00 00 00 00 00 00 00 00 00 00 00 00 00 00 00 00 00 00 00 00 00 00 00 00 00 00 00 00 00 05 01 00 00 0a 00 02 11 00 15 01 00 00 00 00 02 35 00 39 01 00 00 00 00 05 2a 00 00 04 37 39 01 00 00 00 00 05 2b 00 00 09 5f 39 01 00 00 00 00 03 f0 5a 5a 15 01 00 00 00 00 02 b0 01 15 01 00 00 00 00 02 b7 4f 39 01 00 00 00 00 03 f0 a5 a5 39 01 00 00 00 00 03 f0 5a 5a 15 01 00 00 00 00 02 b0 02 39 01 00 00 00 00 05 ec 00 c0 c3 43 15 01 00 00 00 00 02 b0 0d 15 01 00 00 00 00 02 ec 19 15 01 00 00 00 00 02 b0 06 15 01 00 00 00 00 02 e4 d0 39 01 00 00 00 00 03 f0 a5 a5 39 01 00 00 00 00 03 f0 5a 5a 15 01 00 00 00 00 02 b0 36 15 01 00 00 00 00 02 d3 0f 15 01 00 00 00 00 02 f7 03 39 01 00 00 00 00 03 f0 a5 a5 39 01 00 00 00 00 03 f0 5a 5a 39 01 00 00 00 00 03 fc 5a 5a 15 01 00 00 00 00 02 b0 01 39 01 00 00 00 00 04 e4 a6 75 a3 39 01 00 00 00 00 0f e9 11 75 a6 75 a3 8d 06 20 8c a2 4e 00 32 32 39 01 00 00 00 00 03 fc a5 a5 39 01 00 00 00 00 03 f0 a5 a5 39 01 00 00 00 00 03 f0 5a 5a 39 01 00 00 00 00 04 df 83 00 10 15 01 00 00 00 00 02 b0 01 15 01 00 00 00 00 02 e6 01 39 01 00 00 00 00 03 f0 a5 a5 39 01 00 00 00 00 03 f0 5a 5a 39 01 00 00 00 00 03 fc 5a 5a 15 01 00 00 00 00 02 b0 16 15 01 00 00 00 00 02 d1 2e 39 01 00 00 00 00 03 fc a5 a5 39 01 00 00 3c 00 03 f0 a5 a5 39 01 00 00 00 00 03 f0 5a 5a 15 01 00 00 00 00 02 b0 06 15 01 00 00 00 00 02 b7 20 15 01 00 00 00 00 02 b0 05 15 01 00 00 00 00 02 b7 93 39 01 00 00 00 00 03 f0 a5 a5 15 01 00 00 00 00 02 53 20 39 01 00 00 00 00 03 51 00 00 05 01 00 00 00 00 02 29 00 15 01 00 00 00 00 02 60 00];
				qcom,mdss-dsi-off-command = [05 01 00 00 14 00 02 28 00 15 01 00 00 00 00 02 53 20 05 01 00 00 78 00 02 10 00];
				qcom,mdss-dsi-on-command-state = "dsi_lp_mode";
				qcom,mdss-dsi-off-command-state = "dsi_lp_mode";
				qcom,mdss-dsi-timing-switch-command = [15 01 00 00 00 00 02 60 00];
				qcom,mdss-dsi-timing-switch-command-state = "dsi_lp_mode";
				qcom,mdss-dsi-nolp-command = [39 01 00 00 00 00 03 f0 5a 5a 15 00 00 00 00 00 02 b0 0a 15 00 00 00 00 00 02 ee 06 15 00 00 00 00 00 02 b0 0b 39 00 00 00 00 00 03 d8 59 70 15 00 00 00 00 00 02 60 00 15 01 00 00 00 00 02 53 28 39 01 00 00 09 00 03 f0 a5 a5];
				qcom,mdss-dsi-nolp-command-state = "dsi_lp_mode";
				qcom,compression-mode = "dsc";
				qcom,mdss-dsc-slice-height = <0x8>;
				qcom,mdss-dsc-slice-width = <0x21c>;
				qcom,mdss-dsc-slice-per-pkt = <0x2>;
				qcom,mdss-dsc-bit-per-component = <0x8>;
				qcom,mdss-dsc-bit-per-pixel = <0x8>;
				qcom,mdss-dsc-block-prediction-enable;
				mi,mdss-dsi-dimmingon-command = [15 01 00 00 00 00 02 53 28];
				mi,mdss-dsi-dimmingon-command-state = "dsi_hs_mode";
				mi,mdss-dsi-dimmingoff-command = [15 01 00 00 00 00 02 53 20];
				mi,mdss-dsi-dimmingoff-command-state = "dsi_hs_mode";
				mi,mdss-dsi-hbm-on-command = [15 01 00 00 00 00 02 53 e8 39 01 00 00 00 00 03 51 07 ff];
				mi,mdss-dsi-hbm-off-command = [15 01 00 00 00 00 02 53 28 39 01 00 00 00 00 03 51 07 ff];
				mi,mdss-dsi-hbm-on-command-state = "dsi_lp_mode";
				mi,mdss-dsi-hbm-off-command-state = "dsi_lp_mode";
				mi,mdss-dsi-doze-hbm-command = [39 01 00 00 00 00 03 f0 5a 5a 15 00 00 00 00 00 02 60 00 15 00 00 00 00 00 02 b0 0b 39 00 00 00 00 00 03 d8 50 00 15 01 00 00 00 00 02 53 22 39 01 00 00 00 00 03 f0 5a 5a];
				mi,mdss-dsi-doze-lbm-command = [39 01 00 00 00 00 03 f0 5a 5a 15 00 00 00 00 00 02 60 00 15 00 00 00 00 00 02 b0 0b 39 00 00 00 00 00 03 d8 50 00 15 01 00 00 00 00 02 53 23 39 01 00 00 00 00 03 f0 5a 5a];
				mi,mdss-dsi-doze-hbm-command-state = "dsi_lp_mode";
				mi,mdss-dsi-doze-lbm-command-state = "dsi_lp_mode";
				mi,mdss-dsi-flat-mode-on-command = [39 01 00 00 00 00 03 f0 5a 5a 39 00 00 00 00 00 1d c2 2d 27 fe 82 c6 70 82 70 ca 0a 0a 0a 28 28 28 35 35 35 3f 3f 3f 42 42 42 1b da 2f 48 15 01 00 00 00 00 02 f7 03 39 01 00 00 09 00 03 f0 a5 a5];
				mi,mdss-dsi-flat-mode-off-command = [39 01 00 00 00 00 03 f0 5a 5a 39 00 00 00 00 00 1d c2 2d 07 fe 82 c6 70 82 70 ca 0a 0a 0a 28 28 28 35 35 35 3f 3f 3f 42 42 42 1b da 2f 48 15 01 00 00 00 00 02 f7 03 39 01 00 00 09 00 03 f0 a5 a5];
				mi,mdss-dsi-flat-mode-on-command-state = "dsi_lp_mode";
				mi,mdss-dsi-flat-mode-off-command-state = "dsi_lp_mode";
				mi,mdss-dsi-crc-off-command = [39 01 00 00 00 00 02 81 00 39 00 00 00 00 00 03 f0 5a 5a 39 00 00 00 00 00 02 b1 01 39 01 00 00 00 00 03 f0 a5 a5];
				mi,mdss-dsi-crc-off-command-state = "dsi_hs_mode";
				qcom,mdss-dsi-panel-phy-timings = [00 24 0a 0a 1a 19 09 0a 09 02 04 00 1e 0f];
				qcom,display-topology = <0x1 0x1 0x1>;
				qcom,default-topology-index = <0x0>;
			};
		};
	};

	qcom,mdss_dsi_k11_38_08_0a_perf_dsc_cmd {
		qcom,mdss-dsi-panel-name = "xiaomi 38 08 0a perf cmd mode dsc dsi panel";
		qcom,mdss-dsi-panel-type = "dsi_cmd_mode";
		qcom,mdss-dsi-virtual-channel-id = <0x0>;
		qcom,mdss-dsi-stream = <0x0>;
		qcom,mdss-dsi-bpp = <0x18>;
		qcom,mdss-dsi-color-order = "rgb_swap_rgb";
		qcom,mdss-dsi-underflow-color = <0xff>;
		qcom,mdss-dsi-border-color = <0x0>;
		qcom,dsi-ctrl-num = <0x0>;
		qcom,dsi-phy-num = <0x0>;
		qcom,mdss-dsi-traffic-mode = "burst_mode";
		qcom,mdss-dsi-lane-map = "lane_map_0123";
		qcom,mdss-dsi-bllp-eof-power-mode;
		qcom,mdss-dsi-bllp-power-mode;
		qcom,mdss-dsi-lane-0-state;
		qcom,mdss-dsi-lane-1-state;
		qcom,mdss-dsi-lane-2-state;
		qcom,mdss-dsi-lane-3-state;
		qcom,mdss-dsi-dma-trigger = "trigger_sw";
		qcom,mdss-dsi-mdp-trigger = "none";
		qcom,mdss-dsi-reset-sequence = <0x0 0xa 0x1 0xa>;
		qcom,mdss-pan-physical-width-dimension = <0x47>;
		qcom,mdss-pan-physical-height-dimension = <0x99>;
		qcom,mdss-dsi-te-pin-select = <0x1>;
		qcom,mdss-dsi-wr-mem-start = <0x2c>;
		qcom,mdss-dsi-wr-mem-continue = <0x3c>;
		qcom,mdss-dsi-te-dcs-command = <0x1>;
		qcom,mdss-dsi-te-check-enable;
		qcom,mdss-dsi-te-using-te-pin;
		qcom,mdss-dsi-tx-eot-append;
		qcom,mdss-dsi-lp11-init;
		qcom,mdss-dsi-panel-mode-switch;
		qcom,mdss-dsi-bl-inverted-dbv;
		qcom,bl-update-flag = "delay_until_first_frame";
		mi,panel-id = <0x4b3131 0x380801>;
		mi,hbm-51-ctl-flag;
		mi,hbm-off-51-index = <0x1>;
		mi,hbm-on-51-index = <0x1>;
		mi,hbm-bl-min-level = <0x1>;
		mi,hbm-bl-max-level = <0x7ff>;
		mi,esd-err-irq-gpio = <0xffffffff 0x4b 0x2001>;
		mi,panel-on-dimming-delay = <0x78>;
		mi,mdss-dsi-panel-dc-threshold = <0x1b8>;
		mi,mdss-dsi-panel-gamma-update-flag;
		mi,mdss-dsi-panel-gamma-flash-read-total-param = <0x15a>;
		mi,mdss-dsi-panel-gamma-b8-register-length = <0x2c>;
		mi,mdss-dsi-panel-gamma-b9-register-length = <0xed>;
		mi,mdss-dsi-panel-gamma-ba-register-length = <0x3f>;
		mi,mdss-dsi-panel-gamma-update-b8-index = <0x2>;
		mi,mdss-dsi-panel-gamma-update-b9-index = <0x3>;
		mi,mdss-dsi-panel-gamma-update-ba-index = <0x4>;
		qcom,dsi-select-clocks = "mux_byte_clk0", "mux_pixel_clk0";
		qcom,panel-supply-entries = <0x21>;
		qcom,mdss-dsi-bl-pmic-control-type = "bl_ctrl_dcs";
		qcom,mdss-dsi-bl-min-level = <0x2>;
		qcom,mdss-dsi-bl-max-level = <0x7ff>;
		qcom,mdss-brightness-max-level = <0x7ff>;
		qcom,platform-te-gpio = <0xffffffff 0x52 0x0>;
		qcom,platform-reset-gpio = <0xffffffff 0x18 0x0>;

		qcom,mdss-dsi-display-timings {

			timing@0 {
				qcom,mdss-dsi-cmd-mode;
				qcom,mdss-dsi-panel-framerate = <0x90>;
				qcom,mdss-dsi-panel-width = <0x438>;
				qcom,mdss-dsi-panel-height = <0x960>;
				qcom,mdss-dsi-h-front-porch = <0x10>;
				qcom,mdss-dsi-h-back-porch = <0x8>;
				qcom,mdss-dsi-h-pulse-width = <0x8>;
				qcom,mdss-dsi-h-sync-skew = <0x0>;
				qcom,mdss-dsi-v-back-porch = <0x8>;
				qcom,mdss-dsi-v-front-porch = <0x4>;
				qcom,mdss-dsi-v-pulse-width = <0x4>;
				qcom,mdss-dsi-h-sync-pulse = <0x0>;
				qcom,mdss-dsi-h-left-border = <0x0>;
				qcom,mdss-dsi-h-right-border = <0x0>;
				qcom,mdss-dsi-v-top-border = <0x0>;
				qcom,mdss-dsi-v-bottom-border = <0x0>;
				qcom,mdss-dsi-panel-clockrate = <0x4190ab00>;
				qcom,mdss-dsi-panel-jitter = <0x5 0x1>;
				qcom,mdss-mdp-transfer-time-us = <0x1770>;
				qcom,mdss-dsi-on-command = [15 01 00 00 00 00 02 9d 01 39 01 00 00 0a 00 81 9e 11 00 00 89 30 80 09 60 04 38 00 08 02 1c 02 1c 02 00 02 0e 00 20 00 bb 00 07 00 0c 0d b7 0c b7 18 00 10 f0 03 0c 20 00 06 0b 0b 33 0e 1c 2a 38 46 54 62 69 70 77 79 7b 7d 7e 01 02 01 00 09 40 09 be 19 fc 19 fa 19 f8 1a 38 1a 78 1a b6 2a f6 2b 34 2b 74 3b 74 6b f4 00 00 00 00 00 00 00 00 00 00 00 00 00 00 00 00 00 00 00 00 00 00 00 00 00 00 00 00 00 00 00 00 00 00 00 00 00 00 00 00 05 01 00 00 0a 00 02 11 00 15 01 00 00 00 00 02 35 00 39 01 00 00 00 00 05 2a 00 00 04 37 39 01 00 00 00 00 05 2b 00 00 09 5f 39 01 00 00 00 00 03 f0 5a 5a 15 01 00 00 00 00 02 b0 01 15 01 00 00 00 00 02 b7 4f 39 01 00 00 00 00 03 f0 a5 a5 39 01 00 00 00 00 03 f0 5a 5a 15 01 00 00 00 00 02 b0 02 39 01 00 00 00 00 05 ec 00 c0 c3 43 15 01 00 00 00 00 02 b0 0d 15 01 00 00 00 00 02 ec 19 15 01 00 00 00 00 02 b0 06 15 01 00 00 00 00 02 e4 d0 39 01 00 00 00 00 03 f0 a5 a5 39 01 00 00 00 00 03 f0 5a 5a 15 01 00 00 00 00 02 b0 36 15 01 00 00 00 00 02 d3 0f 15 01 00 00 00 00 02 f7 03 39 01 00 00 00 00 03 f0 a5 a5 39 01 00 00 00 00 03 f0 5a 5a 39 01 00 00 00 00 03 fc 5a 5a 15 01 00 00 00 00 02 b0 01 39 01 00 00 00 00 04 e4 a6 75 a3 39 01 00 00 00 00 0f e9 11 75 a6 75 a3 8d 06 20 8c a2 4e 00 32 32 39 01 00 00 00 00 03 fc a5 a5 39 01 00 00 00 00 03 f0 a5 a5 39 01 00 00 00 00 03 f0 5a 5a 39 01 00 00 00 00 04 df 83 00 10 15 01 00 00 00 00 02 b0 01 15 01 00 00 00 00 02 e6 01 39 01 00 00 00 00 03 f0 a5 a5 39 01 00 00 00 00 03 f0 5a 5a 15 01 00 00 00 00 02 b0 04 39 01 00 00 00 00 05 d9 45 40 42 47 15 01 00 00 00 00 02 f7 03 39 01 00 00 3c 00 03 f0 a5 a5 39 01 00 00 00 00 03 f0 5a 5a 15 01 00 00 00 00 02 b0 06 15 01 00 00 00 00 02 b7 20 15 01 00 00 00 00 02 b0 05 15 01 00 00 00 00 02 b7 93 39 01 00 00 00 00 03 f0 a5 a5 15 01 00 00 00 00 02 53 20 39 01 00 00 00 00 03 51 00 00 05 01 00 00 00 00 02 29 00 39 01 00 00 00 00 03 f0 5a 5a 39 01 00 00 00 00 03 fc 5a 5a 15 01 00 00 00 00 02 b0 16 15 01 00 00 00 00 02 d1 10 39 01 00 00 00 00 03 fc a5 a5 39 01 00 00 00 00 03 f0 a5 a5 15 01 00 00 00 00 02 60 10];
				qcom,mdss-dsi-off-command = [05 01 00 00 0a 00 02 28 00 15 01 00 00 00 00 02 53 20 05 01 00 00 78 00 02 10 00];
				qcom,mdss-dsi-on-command-state = "dsi_lp_mode";
				qcom,mdss-dsi-off-command-state = "dsi_lp_mode";
				qcom,mdss-dsi-timing-switch-command = [39 01 00 00 00 00 03 f0 5a 5a 39 01 00 00 00 00 03 fc 5a 5a 15 01 00 00 00 00 02 b0 16 15 01 00 00 00 00 02 d1 10 39 01 00 00 00 00 03 fc a5 a5 39 01 00 00 00 00 03 f0 a5 a5 15 01 00 00 00 00 02 60 10];
				qcom,mdss-dsi-timing-switch-command-state = "dsi_lp_mode";
				qcom,mdss-dsi-nolp-command = [39 01 00 00 00 00 03 f0 5a 5a 15 00 00 00 00 00 02 b0 0a 15 00 00 00 00 00 02 ee 06 15 00 00 00 00 00 02 b0 0b 39 00 00 00 00 00 03 d8 59 70 15 00 00 00 00 00 02 60 10 15 01 00 00 00 00 02 53 28 39 01 00 00 09 00 03 f0 a5 a5];
				qcom,mdss-dsi-nolp-command-state = "dsi_lp_mode";
				qcom,compression-mode = "dsc";
				qcom,mdss-dsc-slice-height = <0x8>;
				qcom,mdss-dsc-slice-width = <0x21c>;
				qcom,mdss-dsc-slice-per-pkt = <0x2>;
				qcom,mdss-dsc-bit-per-component = <0x8>;
				qcom,mdss-dsc-bit-per-pixel = <0x8>;
				qcom,mdss-dsc-block-prediction-enable;
				mi,mdss-dsi-dimmingon-command = [15 01 00 00 00 00 02 53 28];
				mi,mdss-dsi-dimmingon-command-state = "dsi_hs_mode";
				mi,mdss-dsi-dimmingoff-command = [15 01 00 00 00 00 02 53 20];
				mi,mdss-dsi-dimmingoff-command-state = "dsi_hs_mode";
				mi,mdss-dsi-hbm-on-command = [15 01 00 00 00 00 02 53 e8 39 01 00 00 00 00 03 51 07 ff];
				mi,mdss-dsi-hbm-off-command = [15 01 00 00 00 00 02 53 28 39 01 00 00 00 00 03 51 07 ff];
				mi,mdss-dsi-hbm-on-command-state = "dsi_lp_mode";
				mi,mdss-dsi-hbm-off-command-state = "dsi_lp_mode";
				mi,mdss-dsi-gamma-write-command = [39 01 00 00 00 00 03 f0 5a 5a 15 01 00 00 00 00 02 b0 bb 39 01 00 00 00 00 2d b8 00 00 00 00 00 00 00 00 00 00 00 00 00 00 00 00 00 00 00 00 00 00 00 00 00 00 00 00 00 00 00 00 00 00 00 00 00 00 00 00 00 00 00 00 39 01 00 00 00 00 ee b9 00 00 00 00 00 00 00 00 00 00 00 00 00 00 00 00 00 00 00 00 00 00 00 00 00 00 00 00 00 00 00 00 00 00 00 00 00 00 00 00 00 00 00 00 00 00 00 00 00 00 00 00 00 00 00 00 00 00 00 00 00 00 00 00 00 00 00 00 00 00 00 00 00 00 00 00 00 00 00 00 00 00 00 00 00 00 00 00 00 00 00 00 00 00 00 00 00 00 00 00 00 00 00 00 00 00 00 00 00 00 00 00 00 00 00 00 00 00 00 00 00 00 00 00 00 00 00 00 00 00 00 00 00 00 00 00 00 00 00 00 00 00 00 00 00 00 00 00 00 00 00 00 00 00 00 00 00 00 00 00 00 00 00 00 00 00 00 00 00 00 00 00 00 00 00 00 00 00 00 00 00 00 00 00 00 00 00 00 00 00 00 00 00 00 00 00 00 00 00 00 00 00 00 00 00 00 00 00 00 00 00 00 00 00 00 00 00 00 00 00 00 00 00 00 00 00 00 00 00 00 00 00 00 00 00 00 00 39 01 00 00 00 00 40 ba 00 00 00 00 00 00 00 00 00 00 00 00 00 00 00 00 00 00 00 00 00 00 00 00 00 00 00 00 00 00 00 00 00 00 00 00 00 00 00 00 00 00 00 00 00 00 00 00 00 00 00 00 00 00 00 00 00 00 00 00 00 00 00 39 01 00 00 00 00 03 f0 a5 a5];
				mi,mdss-dsi-gamma-write-command-state = "dsi_lp_mode";
				mi,mdss-dsi-gamma-otp-read-pre-command = [39 01 00 00 00 00 03 f0 5a 5a 15 01 00 00 00 00 02 b0 bb];
				mi,mdss-dsi-gamma-otp-read-b8-command = [06 01 00 00 00 00 02 b8 00];
				mi,mdss-dsi-gamma-otp-read-b9-command = [06 01 00 00 00 00 02 b9 00];
				mi,mdss-dsi-gamma-otp-read-ba-command = [06 01 00 00 00 00 02 ba 00];
				mi,mdss-dsi-gamma-otp-read-post-command = [39 01 00 00 00 00 03 f0 a5 a5];
				mi,mdss-dsi-gamma-otp-read-pre-command-state = "dsi_lp_mode";
				mi,mdss-dsi-gamma-otp-read-b8-command-state = "dsi_lp_mode";
				mi,mdss-dsi-gamma-otp-read-b9-command-state = "dsi_lp_mode";
				mi,mdss-dsi-gamma-otp-read-ba-command-state = "dsi_lp_mode";
				mi,mdss-dsi-gamma-otp-read-post-command-state = "dsi_lp_mode";
				mi,mdss-dsi-gamma-flash-read1-pre-command = [39 01 00 00 00 00 03 fc 5a 5a 15 01 00 00 00 00 02 b0 10 39 01 00 00 00 00 03 ff 02 70];
				mi,mdss-dsi-gamma-flash-read2-pre-command = [39 01 00 00 00 00 03 fc 5a 5a 15 01 00 00 00 00 02 b0 10 39 01 00 00 00 00 03 ff 02 71];
				mi,mdss-dsi-gamma-flash-read-f6-command = [06 01 00 00 00 00 02 f6 00];
				mi,mdss-dsi-gamma-flash-read-post-command = [15 01 00 00 00 00 02 b0 10 39 01 00 00 00 00 03 ff 00 70 39 01 00 00 00 00 03 fc a5 a5];
				mi,mdss-dsi-gamma-flash-read1-pre-command-state = "dsi_lp_mode";
				mi,mdss-dsi-gamma-flash-read2-pre-command-state = "dsi_lp_mode";
				mi,mdss-dsi-gamma-flash-read-f6-command-state = "dsi_lp_mode";
				mi,mdss-dsi-gamma-flash-read-post-command-state = "dsi_lp_mode";
				mi,mdss-dsi-doze-hbm-command = [39 01 00 00 00 00 03 f0 5a 5a 15 00 00 00 00 00 02 60 00 15 00 00 00 00 00 02 b0 0b 39 00 00 00 00 00 03 d8 50 00 15 01 00 00 00 00 02 53 22 39 01 00 00 00 00 03 f0 5a 5a];
				mi,mdss-dsi-doze-lbm-command = [39 01 00 00 00 00 03 f0 5a 5a 15 00 00 00 00 00 02 60 00 15 00 00 00 00 00 02 b0 0b 39 00 00 00 00 00 03 d8 50 00 15 01 00 00 00 00 02 53 23 39 01 00 00 00 00 03 f0 5a 5a];
				mi,mdss-dsi-doze-hbm-command-state = "dsi_lp_mode";
				mi,mdss-dsi-doze-lbm-command-state = "dsi_lp_mode";
				mi,mdss-dsi-flat-mode-on-command = [39 01 00 00 00 00 03 f0 5a 5a 39 00 00 00 00 00 1d c2 2d 27 fe 82 c6 70 82 70 ca 0a 0a 0a 28 28 28 35 35 35 3f 3f 3f 42 42 42 1b da 2f 48 15 01 00 00 00 00 02 f7 03 39 01 00 00 09 00 03 f0 a5 a5];
				mi,mdss-dsi-flat-mode-off-command = [39 01 00 00 00 00 03 f0 5a 5a 39 00 00 00 00 00 1d c2 2d 07 fe 82 c6 70 82 70 ca 0a 0a 0a 28 28 28 35 35 35 3f 3f 3f 42 42 42 1b da 2f 48 15 01 00 00 00 00 02 f7 03 39 01 00 00 09 00 03 f0 a5 a5];
				mi,mdss-dsi-flat-mode-on-command-state = "dsi_lp_mode";
				mi,mdss-dsi-flat-mode-off-command-state = "dsi_lp_mode";
				mi,mdss-dsi-crc-off-command = [39 01 00 00 00 00 02 81 00 39 00 00 00 00 00 03 f0 5a 5a 39 00 00 00 00 00 02 b1 01 39 01 00 00 00 00 03 f0 a5 a5];
				mi,mdss-dsi-crc-off-command-state = "dsi_hs_mode";
				qcom,mdss-dsi-panel-phy-timings = [00 24 0a 0a 1a 19 09 0a 09 02 04 00 1e 0f];
				qcom,display-topology = <0x2 0x2 0x1>;
				qcom,default-topology-index = <0x0>;
			};

			timing@1 {
				qcom,mdss-dsi-cmd-mode;
				qcom,mdss-dsi-panel-framerate = <0x5a>;
				qcom,mdss-dsi-panel-width = <0x438>;
				qcom,mdss-dsi-panel-height = <0x960>;
				qcom,mdss-dsi-h-front-porch = <0x10>;
				qcom,mdss-dsi-h-back-porch = <0x8>;
				qcom,mdss-dsi-h-pulse-width = <0x8>;
				qcom,mdss-dsi-h-sync-skew = <0x0>;
				qcom,mdss-dsi-v-back-porch = <0x2bc>;
				qcom,mdss-dsi-v-front-porch = <0x2bc>;
				qcom,mdss-dsi-v-pulse-width = <0x10>;
				qcom,mdss-dsi-h-sync-pulse = <0x0>;
				qcom,mdss-dsi-h-left-border = <0x0>;
				qcom,mdss-dsi-h-right-border = <0x0>;
				qcom,mdss-dsi-v-top-border = <0x0>;
				qcom,mdss-dsi-v-bottom-border = <0x0>;
				qcom,mdss-dsi-panel-clockrate = <0x4190ab00>;
				qcom,mdss-dsi-panel-jitter = <0x5 0x1>;
				qcom,mdss-mdp-transfer-time-us = <0x1770>;
				qcom,mdss-dsi-on-command = [15 01 00 00 00 00 02 9d 01 39 01 00 00 0a 00 81 9e 11 00 00 89 30 80 09 60 04 38 00 08 02 1c 02 1c 02 00 02 0e 00 20 00 bb 00 07 00 0c 0d b7 0c b7 18 00 10 f0 03 0c 20 00 06 0b 0b 33 0e 1c 2a 38 46 54 62 69 70 77 79 7b 7d 7e 01 02 01 00 09 40 09 be 19 fc 19 fa 19 f8 1a 38 1a 78 1a b6 2a f6 2b 34 2b 74 3b 74 6b f4 00 00 00 00 00 00 00 00 00 00 00 00 00 00 00 00 00 00 00 00 00 00 00 00 00 00 00 00 00 00 00 00 00 00 00 00 00 00 00 00 05 01 00 00 0a 00 02 11 00 15 01 00 00 00 00 02 35 00 39 01 00 00 00 00 05 2a 00 00 04 37 39 01 00 00 00 00 05 2b 00 00 09 5f 39 01 00 00 00 00 03 f0 5a 5a 15 01 00 00 00 00 02 b0 01 15 01 00 00 00 00 02 b7 4f 39 01 00 00 00 00 03 f0 a5 a5 39 01 00 00 00 00 03 f0 5a 5a 15 01 00 00 00 00 02 b0 02 39 01 00 00 00 00 05 ec 00 c0 c3 43 15 01 00 00 00 00 02 b0 0d 15 01 00 00 00 00 02 ec 19 15 01 00 00 00 00 02 b0 06 15 01 00 00 00 00 02 e4 d0 39 01 00 00 00 00 03 f0 a5 a5 39 01 00 00 00 00 03 f0 5a 5a 15 01 00 00 00 00 02 b0 36 15 01 00 00 00 00 02 d3 0f 15 01 00 00 00 00 02 f7 03 39 01 00 00 00 00 03 f0 a5 a5 39 01 00 00 00 00 03 f0 5a 5a 39 01 00 00 00 00 03 fc 5a 5a 15 01 00 00 00 00 02 b0 01 39 01 00 00 00 00 04 e4 a6 75 a3 39 01 00 00 00 00 0f e9 11 75 a6 75 a3 8d 06 20 8c a2 4e 00 32 32 39 01 00 00 00 00 03 fc a5 a5 39 01 00 00 00 00 03 f0 a5 a5 39 01 00 00 00 00 03 f0 5a 5a 39 01 00 00 00 00 04 df 83 00 10 15 01 00 00 00 00 02 b0 01 15 01 00 00 00 00 02 e6 01 39 01 00 00 00 00 03 f0 a5 a5 39 01 00 00 00 00 03 f0 5a 5a 15 01 00 00 00 00 02 b0 04 39 01 00 00 00 00 05 d9 45 40 42 47 15 01 00 00 00 00 02 f7 03 39 01 00 00 3c 00 03 f0 a5 a5 39 01 00 00 00 00 03 f0 5a 5a 15 01 00 00 00 00 02 b0 06 15 01 00 00 00 00 02 b7 20 15 01 00 00 00 00 02 b0 05 15 01 00 00 00 00 02 b7 93 39 01 00 00 00 00 03 f0 a5 a5 15 01 00 00 00 00 02 53 20 39 01 00 00 00 00 03 51 00 00 05 01 00 00 00 00 02 29 00 39 01 00 00 00 00 03 f0 5a 5a 39 01 00 00 00 00 03 fc 5a 5a 15 01 00 00 00 00 02 b0 12 15 01 00 00 00 00 02 d1 6b 15 01 00 00 00 00 02 b0 2a 15 01 00 00 00 00 02 d3 2c 15 01 00 00 00 00 02 b0 2e 15 01 00 00 00 00 02 d3 2c 15 01 00 00 00 00 02 f7 03 39 01 00 00 00 00 03 fc a5 a5 39 01 00 00 00 00 03 f0 a5 a5 15 01 00 00 00 00 02 60 00];
				qcom,mdss-dsi-off-command = [05 01 00 00 0a 00 02 28 00 15 01 00 00 00 00 02 53 20 05 01 00 00 78 00 02 10 00];
				qcom,mdss-dsi-on-command-state = "dsi_lp_mode";
				qcom,mdss-dsi-off-command-state = "dsi_lp_mode";
				qcom,mdss-dsi-timing-switch-command = <0x39010000 0x3f0 0x5a5a3901 0x0 0x3fc5a5a 0x15010000 0x2b0 0x12150100 0x2 0xd16b1501 0x0 0x2b02a15 0x1000000 0x2d32c 0x15010000 0x2b0 0x2e150100 0x2 0xd32c1501 0x0 0x2f70339 0x1000000 0x3fca5 0xa5390100 0x3 0xf0a5a515 0x1000000 0x26000>;
				qcom,mdss-dsi-timing-switch-command-state = "dsi_lp_mode";
				qcom,mdss-dsi-nolp-command = [39 01 00 00 00 00 03 f0 5a 5a 15 00 00 00 00 00 02 b0 0a 15 00 00 00 00 00 02 ee 06 15 00 00 00 00 00 02 b0 0b 39 00 00 00 00 00 03 d8 59 70 15 00 00 00 00 00 02 60 00 15 01 00 00 00 00 02 53 28 39 01 00 00 09 00 03 f0 a5 a5];
				qcom,mdss-dsi-nolp-command-state = "dsi_lp_mode";
				qcom,compression-mode = "dsc";
				qcom,mdss-dsc-slice-height = <0x8>;
				qcom,mdss-dsc-slice-width = <0x21c>;
				qcom,mdss-dsc-slice-per-pkt = <0x2>;
				qcom,mdss-dsc-bit-per-component = <0x8>;
				qcom,mdss-dsc-bit-per-pixel = <0x8>;
				qcom,mdss-dsc-block-prediction-enable;
				mi,mdss-dsi-dimmingon-command = [15 01 00 00 00 00 02 53 28];
				mi,mdss-dsi-dimmingon-command-state = "dsi_hs_mode";
				mi,mdss-dsi-dimmingoff-command = [15 01 00 00 00 00 02 53 20];
				mi,mdss-dsi-dimmingoff-command-state = "dsi_hs_mode";
				mi,mdss-dsi-hbm-on-command = [15 01 00 00 00 00 02 53 e8 39 01 00 00 00 00 03 51 07 ff];
				mi,mdss-dsi-hbm-off-command = [15 01 00 00 00 00 02 53 28 39 01 00 00 00 00 03 51 07 ff];
				mi,mdss-dsi-hbm-on-command-state = "dsi_lp_mode";
				mi,mdss-dsi-hbm-off-command-state = "dsi_lp_mode";
				mi,mdss-dsi-gamma-write-command = [39 01 00 00 00 00 03 f0 5a 5a 15 01 00 00 00 00 02 b0 bb 39 01 00 00 00 00 2d b8 00 00 00 00 00 00 00 00 00 00 00 00 00 00 00 00 00 00 00 00 00 00 00 00 00 00 00 00 00 00 00 00 00 00 00 00 00 00 00 00 00 00 00 00 39 01 00 00 00 00 ee b9 00 00 00 00 00 00 00 00 00 00 00 00 00 00 00 00 00 00 00 00 00 00 00 00 00 00 00 00 00 00 00 00 00 00 00 00 00 00 00 00 00 00 00 00 00 00 00 00 00 00 00 00 00 00 00 00 00 00 00 00 00 00 00 00 00 00 00 00 00 00 00 00 00 00 00 00 00 00 00 00 00 00 00 00 00 00 00 00 00 00 00 00 00 00 00 00 00 00 00 00 00 00 00 00 00 00 00 00 00 00 00 00 00 00 00 00 00 00 00 00 00 00 00 00 00 00 00 00 00 00 00 00 00 00 00 00 00 00 00 00 00 00 00 00 00 00 00 00 00 00 00 00 00 00 00 00 00 00 00 00 00 00 00 00 00 00 00 00 00 00 00 00 00 00 00 00 00 00 00 00 00 00 00 00 00 00 00 00 00 00 00 00 00 00 00 00 00 00 00 00 00 00 00 00 00 00 00 00 00 00 00 00 00 00 00 00 00 00 00 00 00 00 00 00 00 00 00 00 00 00 00 00 00 00 00 00 00 39 01 00 00 00 00 40 ba 00 00 00 00 00 00 00 00 00 00 00 00 00 00 00 00 00 00 00 00 00 00 00 00 00 00 00 00 00 00 00 00 00 00 00 00 00 00 00 00 00 00 00 00 00 00 00 00 00 00 00 00 00 00 00 00 00 00 00 00 00 00 00 39 01 00 00 00 00 03 f0 a5 a5];
				mi,mdss-dsi-gamma-write-command-state = "dsi_lp_mode";
				mi,mdss-dsi-gamma-otp-read-pre-command = [39 01 00 00 00 00 03 f0 5a 5a 15 01 00 00 00 00 02 b0 bb];
				mi,mdss-dsi-gamma-otp-read-b8-command = [06 01 00 00 00 00 02 b8 00];
				mi,mdss-dsi-gamma-otp-read-b9-command = [06 01 00 00 00 00 02 b9 00];
				mi,mdss-dsi-gamma-otp-read-ba-command = [06 01 00 00 00 00 02 ba 00];
				mi,mdss-dsi-gamma-otp-read-post-command = [39 01 00 00 00 00 03 f0 a5 a5];
				mi,mdss-dsi-gamma-otp-read-pre-command-state = "dsi_lp_mode";
				mi,mdss-dsi-gamma-otp-read-b8-command-state = "dsi_lp_mode";
				mi,mdss-dsi-gamma-otp-read-b9-command-state = "dsi_lp_mode";
				mi,mdss-dsi-gamma-otp-read-ba-command-state = "dsi_lp_mode";
				mi,mdss-dsi-gamma-otp-read-post-command-state = "dsi_lp_mode";
				mi,mdss-dsi-gamma-flash-read1-pre-command = [39 01 00 00 00 00 03 fc 5a 5a 15 01 00 00 00 00 02 b0 10 39 01 00 00 00 00 03 ff 02 70];
				mi,mdss-dsi-gamma-flash-read2-pre-command = [39 01 00 00 00 00 03 fc 5a 5a 15 01 00 00 00 00 02 b0 10 39 01 00 00 00 00 03 ff 02 71];
				mi,mdss-dsi-gamma-flash-read-f6-command = [06 01 00 00 00 00 02 f6 00];
				mi,mdss-dsi-gamma-flash-read-post-command = [15 01 00 00 00 00 02 b0 10 39 01 00 00 00 00 03 ff 00 70 39 01 00 00 00 00 03 fc a5 a5];
				mi,mdss-dsi-gamma-flash-read1-pre-command-state = "dsi_lp_mode";
				mi,mdss-dsi-gamma-flash-read2-pre-command-state = "dsi_lp_mode";
				mi,mdss-dsi-gamma-flash-read-f6-command-state = "dsi_lp_mode";
				mi,mdss-dsi-gamma-flash-read-post-command-state = "dsi_lp_mode";
				mi,mdss-dsi-doze-hbm-command = [39 01 00 00 00 00 03 f0 5a 5a 15 00 00 00 00 00 02 60 00 15 00 00 00 00 00 02 b0 0b 39 00 00 00 00 00 03 d8 50 00 15 01 00 00 00 00 02 53 22 39 01 00 00 00 00 03 f0 5a 5a];
				mi,mdss-dsi-doze-lbm-command = [39 01 00 00 00 00 03 f0 5a 5a 15 00 00 00 00 00 02 60 00 15 00 00 00 00 00 02 b0 0b 39 00 00 00 00 00 03 d8 50 00 15 01 00 00 00 00 02 53 23 39 01 00 00 00 00 03 f0 5a 5a];
				mi,mdss-dsi-doze-hbm-command-state = "dsi_lp_mode";
				mi,mdss-dsi-doze-lbm-command-state = "dsi_lp_mode";
				mi,mdss-dsi-flat-mode-on-command = [39 01 00 00 00 00 03 f0 5a 5a 39 00 00 00 00 00 1d c2 2d 27 fe 82 c6 70 82 70 ca 0a 0a 0a 28 28 28 35 35 35 3f 3f 3f 42 42 42 1b da 2f 48 15 01 00 00 00 00 02 f7 03 39 01 00 00 09 00 03 f0 a5 a5];
				mi,mdss-dsi-flat-mode-off-command = [39 01 00 00 00 00 03 f0 5a 5a 39 00 00 00 00 00 1d c2 2d 07 fe 82 c6 70 82 70 ca 0a 0a 0a 28 28 28 35 35 35 3f 3f 3f 42 42 42 1b da 2f 48 15 01 00 00 00 00 02 f7 03 39 01 00 00 09 00 03 f0 a5 a5];
				mi,mdss-dsi-flat-mode-on-command-state = "dsi_lp_mode";
				mi,mdss-dsi-flat-mode-off-command-state = "dsi_lp_mode";
				mi,mdss-dsi-crc-off-command = [39 01 00 00 00 00 02 81 00 39 00 00 00 00 00 03 f0 5a 5a 39 00 00 00 00 00 02 b1 01 39 01 00 00 00 00 03 f0 a5 a5];
				mi,mdss-dsi-crc-off-command-state = "dsi_hs_mode";
				qcom,mdss-dsi-panel-phy-timings = [00 24 0a 0a 1a 19 09 0a 09 02 04 00 1e 0f];
				qcom,display-topology = <0x2 0x2 0x1>;
				qcom,default-topology-index = <0x0>;
			};

			timing@2 {
				qcom,mdss-dsi-cmd-mode;
				qcom,mdss-dsi-panel-framerate = <0x3c>;
				qcom,mdss-dsi-panel-width = <0x438>;
				qcom,mdss-dsi-panel-height = <0x960>;
				qcom,mdss-dsi-h-front-porch = <0x10>;
				qcom,mdss-dsi-h-back-porch = <0x8>;
				qcom,mdss-dsi-h-pulse-width = <0x8>;
				qcom,mdss-dsi-h-sync-skew = <0x0>;
				qcom,mdss-dsi-v-back-porch = <0x6a4>;
				qcom,mdss-dsi-v-front-porch = <0x640>;
				qcom,mdss-dsi-v-pulse-width = <0x20>;
				qcom,mdss-dsi-h-sync-pulse = <0x0>;
				qcom,mdss-dsi-h-left-border = <0x0>;
				qcom,mdss-dsi-h-right-border = <0x0>;
				qcom,mdss-dsi-v-top-border = <0x0>;
				qcom,mdss-dsi-v-bottom-border = <0x0>;
				qcom,mdss-dsi-panel-clockrate = <0x4190ab00>;
				qcom,mdss-dsi-panel-jitter = <0x5 0x1>;
				qcom,mdss-mdp-transfer-time-us = <0x1770>;
				qcom,mdss-dsi-on-command = [15 01 00 00 00 00 02 9d 01 39 01 00 00 0a 00 81 9e 11 00 00 89 30 80 09 60 04 38 00 08 02 1c 02 1c 02 00 02 0e 00 20 00 bb 00 07 00 0c 0d b7 0c b7 18 00 10 f0 03 0c 20 00 06 0b 0b 33 0e 1c 2a 38 46 54 62 69 70 77 79 7b 7d 7e 01 02 01 00 09 40 09 be 19 fc 19 fa 19 f8 1a 38 1a 78 1a b6 2a f6 2b 34 2b 74 3b 74 6b f4 00 00 00 00 00 00 00 00 00 00 00 00 00 00 00 00 00 00 00 00 00 00 00 00 00 00 00 00 00 00 00 00 00 00 00 00 00 00 00 00 05 01 00 00 0a 00 02 11 00 15 01 00 00 00 00 02 35 00 39 01 00 00 00 00 05 2a 00 00 04 37 39 01 00 00 00 00 05 2b 00 00 09 5f 39 01 00 00 00 00 03 f0 5a 5a 15 01 00 00 00 00 02 b0 01 15 01 00 00 00 00 02 b7 4f 39 01 00 00 00 00 03 f0 a5 a5 39 01 00 00 00 00 03 f0 5a 5a 15 01 00 00 00 00 02 b0 02 39 01 00 00 00 00 05 ec 00 c0 c3 43 15 01 00 00 00 00 02 b0 0d 15 01 00 00 00 00 02 ec 19 15 01 00 00 00 00 02 b0 06 15 01 00 00 00 00 02 e4 d0 39 01 00 00 00 00 03 f0 a5 a5 39 01 00 00 00 00 03 f0 5a 5a 15 01 00 00 00 00 02 b0 36 15 01 00 00 00 00 02 d3 0f 15 01 00 00 00 00 02 f7 03 39 01 00 00 00 00 03 f0 a5 a5 39 01 00 00 00 00 03 f0 5a 5a 39 01 00 00 00 00 03 fc 5a 5a 15 01 00 00 00 00 02 b0 01 39 01 00 00 00 00 04 e4 a6 75 a3 39 01 00 00 00 00 0f e9 11 75 a6 75 a3 8d 06 20 8c a2 4e 00 32 32 39 01 00 00 00 00 03 fc a5 a5 39 01 00 00 00 00 03 f0 a5 a5 39 01 00 00 00 00 03 f0 5a 5a 39 01 00 00 00 00 04 df 83 00 10 15 01 00 00 00 00 02 b0 01 15 01 00 00 00 00 02 e6 01 39 01 00 00 00 00 03 f0 a5 a5 39 01 00 00 00 00 03 f0 5a 5a 15 01 00 00 00 00 02 b0 04 39 01 00 00 00 00 05 d9 45 40 42 47 15 01 00 00 00 00 02 f7 03 39 01 00 00 3c 00 03 f0 a5 a5 39 01 00 00 00 00 03 f0 5a 5a 15 01 00 00 00 00 02 b0 06 15 01 00 00 00 00 02 b7 20 15 01 00 00 00 00 02 b0 05 15 01 00 00 00 00 02 b7 93 39 01 00 00 00 00 03 f0 a5 a5 15 01 00 00 00 00 02 53 20 39 01 00 00 00 00 03 51 00 00 05 01 00 00 00 00 02 29 00 39 01 00 00 00 00 03 f0 5a 5a 39 01 00 00 00 00 03 fc 5a 5a 15 01 00 00 00 00 02 b0 12 15 01 00 00 00 00 02 d1 e7 15 01 00 00 00 00 02 b0 2a 15 01 00 00 00 00 02 d3 68 15 01 00 00 00 00 02 b0 2e 15 01 00 00 00 00 02 d3 68 15 01 00 00 00 00 02 f7 03 39 01 00 00 00 00 03 fc a5 a5 39 01 00 00 00 00 03 f0 a5 a5 15 01 00 00 00 00 02 60 00];
				qcom,mdss-dsi-off-command = [05 01 00 00 0a 00 02 28 00 15 01 00 00 00 00 02 53 20 05 01 00 00 78 00 02 10 00];
				qcom,mdss-dsi-on-command-state = "dsi_lp_mode";
				qcom,mdss-dsi-off-command-state = "dsi_lp_mode";
				qcom,mdss-dsi-timing-switch-command = <0x39010000 0x3f0 0x5a5a3901 0x0 0x3fc5a5a 0x15010000 0x2b0 0x12150100 0x2 0xd1e71501 0x0 0x2b02a15 0x1000000 0x2d368 0x15010000 0x2b0 0x2e150100 0x2 0xd3681501 0x0 0x2f70339 0x1000000 0x3fca5 0xa5390100 0x3 0xf0a5a515 0x1000000 0x26000>;
				qcom,mdss-dsi-timing-switch-command-state = "dsi_lp_mode";
				qcom,mdss-dsi-nolp-command = [39 01 00 00 00 00 03 f0 5a 5a 15 00 00 00 00 00 02 b0 0a 15 00 00 00 00 00 02 ee 06 15 00 00 00 00 00 02 b0 0b 39 00 00 00 00 00 03 d8 59 70 15 00 00 00 00 00 02 60 00 15 01 00 00 00 00 02 53 28 39 01 00 00 09 00 03 f0 a5 a5];
				qcom,mdss-dsi-nolp-command-state = "dsi_lp_mode";
				qcom,compression-mode = "dsc";
				qcom,mdss-dsc-slice-height = <0x8>;
				qcom,mdss-dsc-slice-width = <0x21c>;
				qcom,mdss-dsc-slice-per-pkt = <0x2>;
				qcom,mdss-dsc-bit-per-component = <0x8>;
				qcom,mdss-dsc-bit-per-pixel = <0x8>;
				qcom,mdss-dsc-block-prediction-enable;
				mi,mdss-dsi-dimmingon-command = [15 01 00 00 00 00 02 53 28];
				mi,mdss-dsi-dimmingon-command-state = "dsi_hs_mode";
				mi,mdss-dsi-dimmingoff-command = [15 01 00 00 00 00 02 53 20];
				mi,mdss-dsi-dimmingoff-command-state = "dsi_hs_mode";
				mi,mdss-dsi-hbm-on-command = [15 01 00 00 00 00 02 53 e8 39 01 00 00 00 00 03 51 07 ff];
				mi,mdss-dsi-hbm-off-command = [15 01 00 00 00 00 02 53 28 39 01 00 00 00 00 03 51 07 ff];
				mi,mdss-dsi-hbm-on-command-state = "dsi_lp_mode";
				mi,mdss-dsi-hbm-off-command-state = "dsi_lp_mode";
				mi,mdss-dsi-gamma-write-command = [39 01 00 00 00 00 03 f0 5a 5a 15 01 00 00 00 00 02 b0 bb 39 01 00 00 00 00 2d b8 00 00 00 00 00 00 00 00 00 00 00 00 00 00 00 00 00 00 00 00 00 00 00 00 00 00 00 00 00 00 00 00 00 00 00 00 00 00 00 00 00 00 00 00 39 01 00 00 00 00 ee b9 00 00 00 00 00 00 00 00 00 00 00 00 00 00 00 00 00 00 00 00 00 00 00 00 00 00 00 00 00 00 00 00 00 00 00 00 00 00 00 00 00 00 00 00 00 00 00 00 00 00 00 00 00 00 00 00 00 00 00 00 00 00 00 00 00 00 00 00 00 00 00 00 00 00 00 00 00 00 00 00 00 00 00 00 00 00 00 00 00 00 00 00 00 00 00 00 00 00 00 00 00 00 00 00 00 00 00 00 00 00 00 00 00 00 00 00 00 00 00 00 00 00 00 00 00 00 00 00 00 00 00 00 00 00 00 00 00 00 00 00 00 00 00 00 00 00 00 00 00 00 00 00 00 00 00 00 00 00 00 00 00 00 00 00 00 00 00 00 00 00 00 00 00 00 00 00 00 00 00 00 00 00 00 00 00 00 00 00 00 00 00 00 00 00 00 00 00 00 00 00 00 00 00 00 00 00 00 00 00 00 00 00 00 00 00 00 00 00 00 00 00 00 00 00 00 00 00 00 00 00 00 00 00 00 00 00 00 39 01 00 00 00 00 40 ba 00 00 00 00 00 00 00 00 00 00 00 00 00 00 00 00 00 00 00 00 00 00 00 00 00 00 00 00 00 00 00 00 00 00 00 00 00 00 00 00 00 00 00 00 00 00 00 00 00 00 00 00 00 00 00 00 00 00 00 00 00 00 00 39 01 00 00 00 00 03 f0 a5 a5];
				mi,mdss-dsi-gamma-write-command-state = "dsi_lp_mode";
				mi,mdss-dsi-gamma-otp-read-pre-command = [39 01 00 00 00 00 03 f0 5a 5a 15 01 00 00 00 00 02 b0 bb];
				mi,mdss-dsi-gamma-otp-read-b8-command = [06 01 00 00 00 00 02 b8 00];
				mi,mdss-dsi-gamma-otp-read-b9-command = [06 01 00 00 00 00 02 b9 00];
				mi,mdss-dsi-gamma-otp-read-ba-command = [06 01 00 00 00 00 02 ba 00];
				mi,mdss-dsi-gamma-otp-read-post-command = [39 01 00 00 00 00 03 f0 a5 a5];
				mi,mdss-dsi-gamma-otp-read-pre-command-state = "dsi_lp_mode";
				mi,mdss-dsi-gamma-otp-read-b8-command-state = "dsi_lp_mode";
				mi,mdss-dsi-gamma-otp-read-b9-command-state = "dsi_lp_mode";
				mi,mdss-dsi-gamma-otp-read-ba-command-state = "dsi_lp_mode";
				mi,mdss-dsi-gamma-otp-read-post-command-state = "dsi_lp_mode";
				mi,mdss-dsi-gamma-flash-read1-pre-command = [39 01 00 00 00 00 03 fc 5a 5a 15 01 00 00 00 00 02 b0 10 39 01 00 00 00 00 03 ff 02 70];
				mi,mdss-dsi-gamma-flash-read2-pre-command = [39 01 00 00 00 00 03 fc 5a 5a 15 01 00 00 00 00 02 b0 10 39 01 00 00 00 00 03 ff 02 71];
				mi,mdss-dsi-gamma-flash-read-f6-command = [06 01 00 00 00 00 02 f6 00];
				mi,mdss-dsi-gamma-flash-read-post-command = [15 01 00 00 00 00 02 b0 10 39 01 00 00 00 00 03 ff 00 70 39 01 00 00 00 00 03 fc a5 a5];
				mi,mdss-dsi-gamma-flash-read1-pre-command-state = "dsi_lp_mode";
				mi,mdss-dsi-gamma-flash-read2-pre-command-state = "dsi_lp_mode";
				mi,mdss-dsi-gamma-flash-read-f6-command-state = "dsi_lp_mode";
				mi,mdss-dsi-gamma-flash-read-post-command-state = "dsi_lp_mode";
				mi,mdss-dsi-doze-hbm-command = [39 01 00 00 00 00 03 f0 5a 5a 15 00 00 00 00 00 02 60 00 15 00 00 00 00 00 02 b0 0b 39 00 00 00 00 00 03 d8 50 00 15 01 00 00 00 00 02 53 22 39 01 00 00 00 00 03 f0 5a 5a];
				mi,mdss-dsi-doze-lbm-command = [39 01 00 00 00 00 03 f0 5a 5a 15 00 00 00 00 00 02 60 00 15 00 00 00 00 00 02 b0 0b 39 00 00 00 00 00 03 d8 50 00 15 01 00 00 00 00 02 53 23 39 01 00 00 00 00 03 f0 5a 5a];
				mi,mdss-dsi-doze-hbm-command-state = "dsi_lp_mode";
				mi,mdss-dsi-doze-lbm-command-state = "dsi_lp_mode";
				mi,mdss-dsi-flat-mode-on-command = [39 01 00 00 00 00 03 f0 5a 5a 39 00 00 00 00 00 1d c2 2d 27 fe 82 c6 70 82 70 ca 0a 0a 0a 28 28 28 35 35 35 3f 3f 3f 42 42 42 1b da 2f 48 15 01 00 00 00 00 02 f7 03 39 01 00 00 09 00 03 f0 a5 a5];
				mi,mdss-dsi-flat-mode-off-command = [39 01 00 00 00 00 03 f0 5a 5a 39 00 00 00 00 00 1d c2 2d 07 fe 82 c6 70 82 70 ca 0a 0a 0a 28 28 28 35 35 35 3f 3f 3f 42 42 42 1b da 2f 48 15 01 00 00 00 00 02 f7 03 39 01 00 00 09 00 03 f0 a5 a5];
				mi,mdss-dsi-flat-mode-on-command-state = "dsi_lp_mode";
				mi,mdss-dsi-flat-mode-off-command-state = "dsi_lp_mode";
				mi,mdss-dsi-crc-off-command = [39 01 00 00 00 00 02 81 00 39 00 00 00 00 00 03 f0 5a 5a 39 00 00 00 00 00 02 b1 01 39 01 00 00 00 00 03 f0 a5 a5];
				mi,mdss-dsi-crc-off-command-state = "dsi_hs_mode";
				qcom,mdss-dsi-panel-phy-timings = [00 24 0a 0a 1a 19 09 0a 09 02 04 00 1e 0f];
				qcom,display-topology = <0x2 0x2 0x1>;
				qcom,default-topology-index = <0x0>;
			};
		};
	};
};

#include "dsi-panel-prim-sim-video.dtsi"
#include "dsi-panel-sec-sim-video.dtsi"

&mdss_mdp {
	qcom,mdss_dsi_k1_43_06_00_sec_cmd {
		qcom,mdss-dsi-panel-name = "xiaomi 43 06 00 cmd mode secondary dsi panel";
		qcom,mdss-dsi-panel-type = "dsi_cmd_mode";
		qcom,mdss-dsi-virtual-channel-id = <0x0>;
		qcom,mdss-dsi-stream = <0x0>;
		qcom,mdss-dsi-bpp = <0x18>;
		qcom,mdss-dsi-color-order = "rgb_swap_rgb";
		qcom,mdss-dsi-underflow-color = <0xff>;
		qcom,mdss-dsi-border-color = <0x0>;
		qcom,dsi-sec-ctrl-num = <0x1>;
		qcom,dsi-sec-phy-num = <0x1>;
		qcom,mdss-dsi-traffic-mode = "burst_mode";
		qcom,mdss-dsi-lane-map = "lane_map_0123";
		qcom,mdss-dsi-bllp-eof-power-mode;
		qcom,mdss-dsi-bllp-power-mode;
		qcom,mdss-dsi-lane-0-state;
		qcom,mdss-dsi-dma-trigger = "trigger_sw";
		qcom,mdss-dsi-mdp-trigger = "none";
		qcom,mdss-dsi-reset-sequence = <0x1 0x1 0x0 0x1 0x1 0xf>;
		qcom,mdss-pan-physical-width-dimension = <0xd>;
		qcom,mdss-pan-physical-height-dimension = <0x1f>;
		qcom,mdss-dsi-te-pin-select = <0x1>;
		qcom,mdss-dsi-wr-mem-start = <0x2c>;
		qcom,mdss-dsi-wr-mem-continue = <0x3c>;
		qcom,mdss-dsi-te-dcs-command = <0x1>;
		qcom,mdss-dsi-te-check-enable;
		qcom,mdss-dsi-te-using-te-pin;
		qcom,mdss-dsi-tx-eot-append;
		qcom,mdss-dsi-lp11-init;
		qcom,mdss-dsi-panel-peak-brightness = <0x401640>;
		qcom,mdss-dsi-panel-blackness-level = <0xc9e>;
		qcom,bl-update-flag = "delay_until_first_frame";
		qcom,dsi-select-sec-clocks = "mux_byte_clk1", "mux_pixel_clk1";
		qcom,panel-sec-supply-entries = <0x25>;
		qcom,mdss-dsi-sec-bl-pmic-control-type = "bl_ctrl_dcs";
		qcom,mdss-dsi-bl-min-level = <0x0>;
		qcom,mdss-dsi-bl-max-level = <0xff>;
		qcom,mdss-brightness-max-level = <0xff>;
		qcom,platform-te-gpio = <0xffffffff 0x53 0x0>;
		qcom,platform-sec-reset-gpio = <0xffffffff 0x1e 0x0>;

		qcom,mdss-dsi-display-timings {

			timing@0 {
				qcom,mdss-dsi-panel-framerate = <0x3c>;
				qcom,mdss-dsi-panel-width = <0x7e>;
				qcom,mdss-dsi-panel-height = <0x126>;
				qcom,mdss-dsi-h-front-porch = <0x10>;
				qcom,mdss-dsi-h-back-porch = <0x8>;
				qcom,mdss-dsi-h-pulse-width = <0x8>;
				qcom,mdss-dsi-h-sync-skew = <0x0>;
				qcom,mdss-dsi-v-back-porch = <0x20>;
				qcom,mdss-dsi-v-front-porch = <0x20>;
				qcom,mdss-dsi-v-pulse-width = <0x20>;
				qcom,mdss-dsi-h-sync-pulse = <0x0>;
				qcom,mdss-dsi-h-left-border = <0x0>;
				qcom,mdss-dsi-h-right-border = <0x0>;
				qcom,mdss-dsi-v-top-border = <0x0>;
				qcom,mdss-dsi-v-bottom-border = <0x0>;
				qcom,mdss-dsi-panel-clockrate = <0x549e990>;
				qcom,mdss-dsi-panel-jitter = <0x5 0x1>;
				qcom,mdss-dsi-on-command = <0x15010000 0x2fe 0x1150100 0x2 0x4201501 0x0 0x2690215 0x1000000 0x26a11 0x15010000 0x26b 0x3d150100 0x2 0x6e001501 0x0 0x2fe0015 0x1000000 0x2c400 0x15010000 0x235 0x390100 0x5 0x2a000000 0x7d150100 0x2 0x51ff0501 0x7800 0x2110005 0x100001e 0x22900>;
				qcom,mdss-dsi-off-command = [05 01 00 00 14 00 02 28 00 05 01 00 00 78 00 02 10 00];
				qcom,mdss-dsi-on-command-state = "dsi_lp_mode";
				qcom,mdss-dsi-off-command-state = "dsi_lp_mode";
				qcom,mdss-dsi-panel-phy-timings = [03 08 00 01 0e 1b 01 01 01 02 02 04 08 06];
				qcom,display-topology = <0x1 0x0 0x1>;
				qcom,default-topology-index = <0x0>;
			};
		};
	};

	qcom,mdss_dsi_k1_43_06_00_sec_video {
		qcom,mdss-dsi-panel-name = "xiaomi 43 06 00 cmd mode secondary dsi panel";
		qcom,mdss-dsi-panel-type = "dsi_video_mode";
		qcom,mdss-dsi-virtual-channel-id = <0x0>;
		qcom,mdss-dsi-stream = <0x0>;
		qcom,mdss-dsi-bpp = <0x18>;
		qcom,mdss-dsi-color-order = "rgb_swap_rgb";
		qcom,mdss-dsi-underflow-color = <0xff>;
		qcom,mdss-dsi-border-color = <0x0>;
		qcom,dsi-sec-ctrl-num = <0x1>;
		qcom,dsi-sec-phy-num = <0x1>;
		qcom,mdss-dsi-traffic-mode = "burst_mode";
		qcom,mdss-dsi-lane-map = "lane_map_0123";
		qcom,mdss-dsi-bllp-eof-power-mode;
		qcom,mdss-dsi-bllp-power-mode;
		qcom,mdss-dsi-lane-0-state;
		qcom,mdss-dsi-dma-trigger = "trigger_sw";
		qcom,mdss-dsi-mdp-trigger = "none";
		qcom,mdss-dsi-reset-sequence = <0x1 0x1 0x0 0x1 0x1 0xf>;
		qcom,mdss-pan-physical-width-dimension = <0xd>;
		qcom,mdss-pan-physical-height-dimension = <0x1f>;
		qcom,mdss-dsi-te-pin-select = <0x1>;
		qcom,mdss-dsi-wr-mem-start = <0x2c>;
		qcom,mdss-dsi-wr-mem-continue = <0x3c>;
		qcom,mdss-dsi-te-dcs-command = <0x1>;
		qcom,mdss-dsi-panel-peak-brightness = <0x401640>;
		qcom,mdss-dsi-panel-blackness-level = <0xc9e>;
		qcom,bl-update-flag = "delay_until_first_frame";
		qcom,dsi-select-sec-clocks = "mux_byte_clk1", "mux_pixel_clk1";
		qcom,panel-sec-supply-entries = <0x25>;
		qcom,mdss-dsi-sec-bl-pmic-control-type = "bl_ctrl_dcs";
		qcom,mdss-dsi-bl-min-level = <0x0>;
		qcom,mdss-dsi-bl-max-level = <0xff>;
		qcom,mdss-brightness-max-level = <0xff>;
		qcom,platform-te-gpio = <0xffffffff 0x53 0x0>;
		qcom,platform-sec-reset-gpio = <0xffffffff 0x1e 0x0>;

		qcom,mdss-dsi-display-timings {

			timing@0 {
				qcom,mdss-dsi-panel-framerate = <0x3c>;
				qcom,mdss-dsi-panel-width = <0x7e>;
				qcom,mdss-dsi-panel-height = <0x126>;
				qcom,mdss-dsi-h-front-porch = <0x10>;
				qcom,mdss-dsi-h-back-porch = <0x8>;
				qcom,mdss-dsi-h-pulse-width = <0x8>;
				qcom,mdss-dsi-h-sync-skew = <0x0>;
				qcom,mdss-dsi-v-back-porch = <0x20>;
				qcom,mdss-dsi-v-front-porch = <0x20>;
				qcom,mdss-dsi-v-pulse-width = <0x20>;
				qcom,mdss-dsi-h-sync-pulse = <0x0>;
				qcom,mdss-dsi-h-left-border = <0x0>;
				qcom,mdss-dsi-h-right-border = <0x0>;
				qcom,mdss-dsi-v-top-border = <0x0>;
				qcom,mdss-dsi-v-bottom-border = <0x0>;
				qcom,mdss-dsi-panel-clockrate = <0x549e990>;
				qcom,mdss-dsi-panel-jitter = <0x5 0x1>;
				qcom,mdss-dsi-on-command = <0x15010000 0x2fe 0x1150100 0x2 0x4201501 0x0 0x2690215 0x1000000 0x26a11 0x15010000 0x26b 0x3d150100 0x2 0x6e001501 0x0 0x2fe0015 0x1000000 0x2c400 0x15010000 0x235 0x390100 0x5 0x2a000000 0x7d150100 0x2 0x51ff0501 0x7800 0x2110005 0x100001e 0x22900>;
				qcom,mdss-dsi-off-command = [05 01 00 00 14 00 02 28 00 05 01 00 00 78 00 02 10 00];
				qcom,mdss-dsi-on-command-state = "dsi_lp_mode";
				qcom,mdss-dsi-off-command-state = "dsi_lp_mode";
				qcom,mdss-dsi-panel-phy-timings = [03 08 00 01 0e 1b 01 01 01 02 02 04 08 06];
				qcom,display-topology = <0x1 0x0 0x1>;
				qcom,default-topology-index = <0x0>;
			};
		};
	};
};

&soc {
	dsi_panel_pwr_supply: dsi_panel_pwr_supply {
		#address-cells = <1>;
		#size-cells = <0>;

		qcom,panel-supply-entry@0 {
			reg = <0>;
			qcom,supply-name = "vddio";
			qcom,supply-min-voltage = <1800000>;
			qcom,supply-max-voltage = <1800000>;
			qcom,supply-enable-load = <60700>;
			qcom,supply-disable-load = <80>;
			qcom,supply-post-on-sleep = <20>;
		};

		qcom,panel-supply-entry@1 {
			reg = <1>;
			qcom,supply-name = "vdd";
			qcom,supply-min-voltage = <3000000>;
			qcom,supply-max-voltage = <3000000>;
			qcom,supply-enable-load = <10000>;
			qcom,supply-disable-load = <0>;
			qcom,supply-post-on-sleep = <0>;
		};

		qcom,panel-supply-entry@2 {
			reg = <2>;
			qcom,supply-name = "lab";
			qcom,supply-min-voltage = <4600000>;
			qcom,supply-max-voltage = <6000000>;
			qcom,supply-enable-load = <0>;
			qcom,supply-disable-load = <0>;
		};

		qcom,panel-supply-entry@3 {
			reg = <3>;
			qcom,supply-name = "ibb";
			qcom,supply-min-voltage = <4600000>;
			qcom,supply-max-voltage = <6000000>;
			qcom,supply-enable-load = <0>;
			qcom,supply-disable-load = <0>;
			qcom,supply-post-on-sleep = <20>;
		};
	};

	dsi_panel_pwr_supply_avdd: dsi_panel_pwr_supply_avdd {
		#address-cells = <1>;
		#size-cells = <0>;

		qcom,panel-supply-entry@0 {
			reg = <0>;
			qcom,supply-name = "vddio";
			qcom,supply-min-voltage = <1800000>;
			qcom,supply-max-voltage = <1800000>;
			qcom,supply-enable-load = <182000>;
			qcom,supply-disable-load = <80>;
			qcom,supply-post-on-sleep = <20>;
		};

		qcom,panel-supply-entry@1 {
			reg = <1>;
			qcom,supply-name = "avdd";
			qcom,supply-min-voltage = <4600000>;
			qcom,supply-max-voltage = <6000000>;
			qcom,supply-enable-load = <100000>;
			qcom,supply-disable-load = <100>;
		};
	};

	dsi_panel_pwr_supply_k2: dsi_panel_pwr_supply_k2 {
		#address-cells = <1>;
		#size-cells = <0>;

		qcom,panel-supply-entry@0 {
			reg = <0>;
			qcom,supply-name = "vddio";
			qcom,supply-min-voltage = <1800000>;
			qcom,supply-max-voltage = <1800000>;
			qcom,supply-enable-load = <60700>;
			qcom,supply-disable-load = <80>;
		};

		qcom,panel-supply-entry@1 {
			reg = <1>;
			qcom,supply-name = "vdd";
			qcom,supply-min-voltage = <3000000>;
			qcom,supply-max-voltage = <3000000>;
			qcom,supply-enable-load = <10000>;
			qcom,supply-disable-load = <0>;
			qcom,supply-pre-off-sleep = <10>;
		};
	};

	dsi_panel_pwr_supply_prim: dsi_panel_pwr_supply_prim {
	#address-cells = <1>;
	#size-cells = <0>;

		qcom,panel-supply-entry@0 {
			reg = <0>;
			qcom,supply-name = "vddio";
			qcom,supply-min-voltage = <1900000>;
			qcom,supply-max-voltage = <1900000>;
			qcom,supply-enable-load = <62000>;
			qcom,supply-disable-load = <80>;
			qcom,supply-pre-on-sleep = <0>;
			qcom,supply-pre-off-sleep = <3>;
			qcom,supply-post-on-sleep = <3>;
			qcom,supply-post-off-sleep = <0>;
		};

		qcom,panel-supply-entry@1 {
			reg = <1>;
			qcom,supply-name = "vdd";
			qcom,supply-min-voltage = <3000000>;
			qcom,supply-max-voltage = <3000000>;
			qcom,supply-enable-load = <100000>;
			qcom,supply-disable-load = <100>;
			qcom,supply-pre-on-sleep = <0>;
			qcom,supply-pre-off-sleep = <2>;
			qcom,supply-post-on-sleep = <10>;
			qcom,supply-post-off-sleep = <0>;
		};
	};

	dsi_panel_pwr_supply_sec: dsi_panel_pwr_supply_sec {
	#address-cells = <1>;
	#size-cells = <0>;

		qcom,panel-supply-entry@0 {
			reg = <0>;
			qcom,supply-name = "sec-vddio";
			qcom,supply-min-voltage = <1800000>;
			qcom,supply-max-voltage = <1800000>;
			qcom,supply-enable-load = <62000>;
			qcom,supply-disable-load = <80>;
			qcom,supply-pre-on-sleep = <0>;
			qcom,supply-pre-off-sleep = <2>;
			qcom,supply-post-on-sleep = <3>;
			qcom,supply-post-off-sleep = <0>;
		};

		qcom,panel-supply-entry@1 {
			reg = <1>;
			qcom,supply-name = "sec-vdd";
			qcom,supply-min-voltage = <3000000>;
			qcom,supply-max-voltage = <3000000>;
			qcom,supply-enable-load = <100000>;
			qcom,supply-disable-load = <100>;
			qcom,supply-pre-on-sleep = <0>;
			qcom,supply-pre-off-sleep = <1>;
			qcom,supply-post-on-sleep = <10>;
			qcom,supply-post-off-sleep = <0>;
		};
	};

	dsi_panel_pwr_supply_sec_k1: dsi_panel_pwr_supply_sec_k1 {
	#address-cells = <1>;
	#size-cells = <0>;

		qcom,panel-supply-entry@0 {
			reg = <0>;
			qcom,supply-name = "sec-vddio";
			qcom,supply-min-voltage = <1800000>;
			qcom,supply-max-voltage = <1800000>;
			qcom,supply-enable-load = <62000>;
			qcom,supply-disable-load = <80>;
			qcom,supply-pre-on-sleep = <0>;
			qcom,supply-pre-off-sleep = <2>;
			qcom,supply-post-on-sleep = <3>;
			qcom,supply-post-off-sleep = <0>;
		};

		qcom,panel-supply-entry@1 {
			reg = <1>;
			qcom,supply-name = "sec-vdd";
			qcom,supply-min-voltage = <3000000>;
			qcom,supply-max-voltage = <3000000>;
			qcom,supply-enable-load = <100000>;
			qcom,supply-disable-load = <100>;
			qcom,supply-pre-on-sleep = <0>;
			qcom,supply-pre-off-sleep = <1>;
			qcom,supply-post-on-sleep = <10>;
			qcom,supply-post-off-sleep = <0>;
		};
	};

	sde_dsi: qcom,dsi-display-primary {
		compatible = "qcom,dsi-display";
		label = "primary";

		qcom,dsi-ctrl = <&mdss_dsi0 &mdss_dsi1>;
		qcom,dsi-phy = <&mdss_dsi_phy0 &mdss_dsi_phy1>;

		qcom,mdp = <&mdss_mdp>;
		qcom,dsi-default-panel = <&dsi_sw43404_amoled_cmd>;
	};

	sde_dsi1: qcom,dsi-display-secondary {
		compatible = "qcom,dsi-display";
		label = "secondary";
		status = "disabled";

		qcom,dsi-ctrl = <&mdss_dsi0 &mdss_dsi1>;
		qcom,dsi-phy = <&mdss_dsi_phy0 &mdss_dsi_phy1>;
		qcom,mdp = <&mdss_mdp>;
	};
};

/* PHY TIMINGS REVISION YC with reduced margins*/
&dsi_sw43404_amoled_cmd {
	qcom,dsi-select-clocks = "mux_byte_clk0", "mux_pixel_clk0";
	qcom,dsi-dyn-clk-enable;
	qcom,dsi-dyn-clk-list = <606979440 604450359 601921278>;

	qcom,dsi-panel-gpio-address = <0x0F100000 0x1000>;
	qcom,dsi-panel-gpio-pins = <12 24 82>;

	qcom,mdss-dsi-display-timings {
		timing@0 {
			qcom,mdss-dsi-panel-phy-timings = [00 14 05 05 13 13 05
				05 06 02 04 00 12 0a];
			qcom,display-topology = <2 2 1>;
			qcom,default-topology-index = <0>;

			qcom,panel-roi-alignment = <720 180 180 180 1440 180>;
		};
	};
};

&dsi_sw43404_amoled_video {
	qcom,mdss-dsi-qsync-min-refresh-rate = <55>;
	qcom,dsi-select-clocks = "mux_byte_clk0", "mux_pixel_clk0",
			"src_byte_clk0", "src_pixel_clk0",
			"shadow_byte_clk0", "shadow_pixel_clk0";
	qcom,dsi-dyn-clk-enable;
	qcom,dsi-dyn-clk-list = <534712320 532484352 530256384>;
	qcom,dsi-dyn-clk-type = "constant-fps-adjust-hfp";

	qcom,mdss-dsi-display-timings {
		timing@0 {
			qcom,mdss-dsi-panel-phy-timings = [00 14 05 05 13 1f 05
				05 06 02 04 00 12 0a];
			qcom,display-topology = <2 2 1>;
			qcom,default-topology-index = <0>;
		};
	};
};

&dsi_r66451_amoled_video {
	qcom,dsi-select-clocks = "mux_byte_clk0", "mux_pixel_clk0";
	qcom,dsi-supported-dfps-list = <120 90 60>;
	qcom,mdss-dsi-pan-enable-dynamic-fps;
	qcom,mdss-dsi-min-refresh-rate = <60>;
	qcom,mdss-dsi-max-refresh-rate = <120>;
	qcom,mdss-dsi-pan-fps-update = "dfps_immediate_porch_mode_vfp";
	qcom,mdss-dsi-display-timings {
		timing@0 {
			qcom,mdss-dsi-panel-phy-timings = [00 1d 08 07 17 16 07
				07 08 02 04 00 19 0c];
			qcom,display-topology = <2 2 1>;
			qcom,default-topology-index = <0>;
		};
	};
};

&dsi_r66451_amoled_cmd {
	qcom,dsi-select-clocks = "mux_byte_clk0", "mux_pixel_clk0";
	qcom,dsi-select-sec-clocks = "mux_byte_clk1", "mux_pixel_clk1";
	qcom,mdss-dsi-display-timings {
		timing@0 {
			qcom,mdss-dsi-panel-phy-timings = [00 10 04 04 12 1e 04
				04 03 02 04 00 0e 09];
			qcom,display-topology = <2 2 1>;
			qcom,default-topology-index = <0>;
		};

		timing@1 {
			qcom,mdss-dsi-panel-phy-timings = [00 16 06 05 14 1f 06
				06 06 02 04 00 14 0a];
			qcom,display-topology = <2 2 1>;
			qcom,default-topology-index = <0>;
		};

		timing@2 {
			qcom,mdss-dsi-panel-phy-timings = [00 1c 08 07 17 16 07
				07 08 02 04 00 19 0c];
			qcom,display-topology = <2 2 1>;
			qcom,default-topology-index = <0>;
		};
	};
};

&dsi_r66451_amoled_cmd_cphy {
	qcom,dsi-select-clocks = "mux_byte_clk0", "mux_pixel_clk0",
			"cphy_byte_clk0", "cphy_pixel_clk0";
	qcom,mdss-dsi-display-timings {
		timing@0 {
			qcom,mdss-dsi-panel-phy-timings = [00 00 00 00 1e 17 04
				19 03 02 04 00 00 00];
			qcom,display-topology = <2 2 1>;
			qcom,default-topology-index = <0>;
		};
	};
};

&dsi_r66451_amoled_video_cphy {
	qcom,dsi-select-clocks = "mux_byte_clk0", "mux_pixel_clk0",
			"cphy_byte_clk0", "cphy_pixel_clk0";
	qcom,mdss-dsi-display-timings {
		timing@0 {
			qcom,mdss-dsi-panel-phy-timings = [00 00 00 00 1e 17 04
				19 03 02 04 00 00 00];
			qcom,display-topology = <2 2 1>;
			qcom,default-topology-index = <0>;
		};
	};
};

&dsi_r66451_amoled_144hz_cmd {
	qcom,dsi-select-clocks = "mux_byte_clk0", "mux_pixel_clk0";
	qcom,dsi-select-sec-clocks = "mux_byte_clk1", "mux_pixel_clk1";
	qcom,mdss-dsi-display-timings {
		timing@0 {
			qcom,mdss-dsi-panel-phy-timings = [00 22 09 09 19 17 09
				09 09 02 04 00 1d 0e];
			qcom,display-topology = <2 2 1>;
			qcom,default-topology-index = <0>;
		};
	};
};

&dsi_sharp_4k_dsc_cmd {
	qcom,dsi-select-clocks = "mux_byte_clk0", "mux_pixel_clk0";
	qcom,mdss-dsi-display-timings {
		timing@0 {
			qcom,mdss-dsi-panel-phy-timings = [00 13 05 04 13 12 05
				05 06 02 04 00 12 09];
			qcom,display-topology = <2 2 2>;
			qcom,default-topology-index = <0>;
		};
	};
};

&dsi_sharp_4k_dsc_video {
	qcom,dsi-select-clocks = "mux_byte_clk0", "mux_pixel_clk0";
	qcom,dsi-select-clocks = "mux_byte_clk0", "mux_pixel_clk0";
	qcom,mdss-dsi-display-timings {
		timing@0 {
			qcom,mdss-dsi-panel-phy-timings = [00 18 06 06 15 14 06
				06 07 02 04 00 15 0b];
			qcom,display-topology = <2 2 2>;
			qcom,default-topology-index = <0>;
		};
	};
};

&dsi_sharp_1080_cmd {
	qcom,dsi-select-clocks = "mux_byte_clk0", "mux_pixel_clk0";
	qcom,mdss-dsi-display-timings {
		timing@0 {
			qcom,mdss-dsi-panel-phy-timings = [00 1e 08 07 18 22 08
				08 08 02 04 00 1a 0c];
			qcom,display-topology = <1 0 1>;
			qcom,default-topology-index = <0>;
			qcom,mdss-dsi-panel-clockrate = <900000000>;
		};
	};
};

&dsi_sharp_qsync_wqhd_cmd {
	qcom,dsi-select-clocks = "mux_byte_clk0", "mux_pixel_clk0";
	qcom,mdss-dsi-display-timings {
		timing@0 { /* WQHD 60FPS CMD */
			qcom,mdss-dsi-panel-phy-timings = [00 0b 03 02 10 1c 03
				03 02 02 04 00 0b 07];
			qcom,display-topology = <2 2 2>;
			qcom,default-topology-index = <0>;
		};

		timing@1 { /* WQHD 60FPS VID */
			qcom,mdss-dsi-panel-phy-timings = [00 13 05 04 13 1e 05
				05 06 02 04 00 12 09];
			qcom,display-topology = <2 2 2>;
			qcom,default-topology-index = <0>;
		};

		timing@2 { /* FHD 60FPS CMD */
			qcom,mdss-dsi-panel-phy-timings = [00 0a 01 02 0e 1b 02
				02 01 02 04 00 09 07];
			qcom,display-topology = <2 2 2>;
			qcom,default-topology-index = <0>;
		};

		timing@3 { /* WQHD 90FPS CMD */
			qcom,mdss-dsi-panel-phy-timings = [00 10 03 03 11 1e 04
				04 03 02 04 00 0e 08];
			qcom,display-topology = <2 2 2>;
			qcom,default-topology-index = <0>;
		};

		timing@4 { /* WQHD 120FPS CMD */
			qcom,mdss-dsi-panel-phy-timings = [00 13 05 04 13 12 05
				 05 06 02 04 00 12 09];
			qcom,display-topology = <2 2 2>;
			qcom,default-topology-index = <0>;
		};

		timing@5 { /* WQHD 120FPS VID */
			qcom,mdss-dsi-panel-phy-timings = [00 13 05 04 13 12 05
				 05 06 02 04 00 12 09];
			qcom,display-topology = <2 2 2>;
			qcom,default-topology-index = <0>;
		};

		timing@6 { /* FHD 120FPS CMD */
			qcom,mdss-dsi-panel-phy-timings = [00 0d 03 03 10 10 03
				03 02 02 04 00 0c 08];
			qcom,display-topology = <2 2 2>;
			qcom,default-topology-index = <0>;
		};

		timing@7 { /* FHD 90FPS CMD */
			qcom,mdss-dsi-panel-phy-timings = [00 0b 02 02 0f 1c 03
				02 02 02 04 00 0a 07];
			qcom,display-topology = <2 2 2>;
			qcom,default-topology-index = <0>;
		};
	};
};

&dsi_sharp_qsync_wqhd_video {
	qcom,dsi-select-clocks = "mux_byte_clk0", "mux_pixel_clk0";
	qcom,mdss-dsi-display-timings {
		timing@0 {
			qcom,mdss-dsi-panel-phy-timings = [00 13 05 04 13 1e 05
				05 06 02 04 00 12 09];
			qcom,display-topology = <2 2 2>;
			qcom,default-topology-index = <0>;
		};
	};
};

&dsi_sharp_qhd_plus_dsc_cmd {
	qcom,dsi-select-clocks = "mux_byte_clk0", "mux_pixel_clk0";
	qcom,mdss-dsi-display-timings {
		timing@0 { /* 120 FPS */
			qcom,mdss-dsi-panel-phy-timings = [00 16 05 05 14 13 06
				06 06 02 04 00 13 0a];
			qcom,display-topology = <2 2 2>;
			qcom,default-topology-index = <0>;
		};

		timing@1 { /* 60 FPS*/
			qcom,mdss-dsi-panel-phy-timings = [00 1a 07 06 16 15 07
				07 07 02 04 00 17 0b];
			qcom,display-topology = <2 2 2>;
			qcom,default-topology-index = <0>;
		};
	};
};

&dsi_dual_nt35597_truly_cmd {
	qcom,dsi-select-clocks = "mux_byte_clk0", "mux_pixel_clk0";
	qcom,mdss-dsi-display-timings {
		timing@0 {
			 /* DPHY regular margins */
			qcom,mdss-dsi-panel-phy-timings = [00 19 06 06 21 20 06
				06 07 02 04 00 17 16 ];
			qcom,display-topology = <2 0 2>,
						<1 0 2>;
			qcom,default-topology-index = <0>;
		};
	};
};

&dsi_dual_nt35597_truly_video {
	qcom,dsi-supported-dfps-list = <60 57 55>;
	qcom,mdss-dsi-pan-enable-dynamic-fps;
	qcom,mdss-dsi-min-refresh-rate = <53>;
	qcom,mdss-dsi-max-refresh-rate = <60>;
	qcom,mdss-dsi-pan-fps-update = "dfps_immediate_porch_mode_vfp";
	qcom,dsi-select-clocks = "mux_byte_clk0", "mux_pixel_clk0";
	qcom,mdss-dsi-display-timings {
		timing@0 {
			qcom,mdss-dsi-panel-phy-timings = [00 1c 07 07 17 15 07
				07 08 02 04 00 18 0c];
			qcom,display-topology = <2 0 2>,
						<1 0 2>;
			qcom,default-topology-index = <0>;
		};
	};
};

&dsi_nt35695b_truly_fhd_cmd {
	qcom,dsi-select-clocks = "mux_byte_clk0", "mux_pixel_clk0";
	qcom,dsi-select-sec-clocks = "mux_byte_clk1", "mux_pixel_clk1";
	qcom,mdss-dsi-display-timings {
		timing@0 {
			/* DPHY regular margins */
			qcom,mdss-dsi-panel-phy-timings = [00 1b 07 06 22 21 07
				07 07 02 04 00 18 16];
			qcom,display-topology = <1 0 1>;
			qcom,default-topology-index = <0>;
		};
	};
};

&dsi_sim_cmd {
	qcom,dsi-select-clocks = "mux_byte_clk0", "mux_pixel_clk0";
	qcom,poms-align-panel-vsync;
	qcom,mdss-dsi-display-timings {
		timing@0 { /* WQHD 60FPS cmd mode*/
			qcom,mdss-dsi-panel-phy-timings = [00 15 06 05 0a 09 06
				06 04 02 04 00 12 0a];
			qcom,display-topology = <1 1 1>,
						<2 2 1>;
			qcom,default-topology-index = <1>;
		};

		timing@1 { /* WQHD 60FPS vid mode*/
			qcom,mdss-dsi-panel-phy-timings = [00 15 06 05 0a 09 06
				06 04 02 04 00 12 0a];
			qcom,display-topology = <1 1 1>,
						<2 2 1>;
			qcom,default-topology-index = <1>;
		};

		timing@2 { /* WQHD 60FPS cmd mode*/
			qcom,mdss-dsi-panel-phy-timings = [00 15 06 06 0a 09 06
				06 04 02 04 00 12 0b];
			qcom,display-topology = <1 1 1>,
						<2 2 1>;
			qcom,default-topology-index = <1>;
		};

		timing@3 { /* FHD 60FPS cmd mode*/
			qcom,mdss-dsi-panel-phy-timings = [00 1c 08 07 0d 0c 08
				08 05 02 04 00 17 0c];
			qcom,display-topology = <1 1 1>,
						<2 2 1>;
			qcom,default-topology-index = <1>;
		};

		timing@4 { /* HD 60FPS cmd mode*/
			qcom,mdss-dsi-panel-phy-timings = [00 24 0a 09 10 0e 0a
				0a 07 02 04 00 1d 0e];
			qcom,display-topology = <1 1 1>,
						<2 2 1>;
			qcom,default-topology-index = <1>;
		};
	};
};

&dsi_sim_vid {
	qcom,dsi-select-clocks = "mux_byte_clk0", "mux_pixel_clk0";
	qcom,mdss-dsi-display-timings {
		timing@0 {
			qcom,mdss-dsi-panel-phy-timings = [01 05 01 01 03 03 01
				01 01 02 04 00 06 06];
			qcom,display-topology = <1 0 1>,
						<2 0 1>;
			qcom,default-topology-index = <0>;
		};
	};
};

&dsi_sim_vdc_cmd {
	qcom,dsi-select-clocks = "mux_byte_clk0", "mux_pixel_clk0";
	qcom,mdss-dsi-display-timings {
		timing@0 {
			qcom,mdss-dsi-panel-phy-timings = [01 05 01 01 03 03 01
				01 01 02 04 00 06 06];
			qcom,display-topology = <2 1 1>;
			qcom,default-topology-index = <0>;
		};
	};
};

&dsi_sim_vdc_vid {
	qcom,dsi-select-clocks = "mux_byte_clk0", "mux_pixel_clk0";
	qcom,mdss-dsi-display-timings {
		timing@0 {
			qcom,mdss-dsi-panel-phy-timings = [01 05 01 01 03 03 01
				01 01 02 04 00 06 06];
			qcom,display-topology = <2 1 1>;
			qcom,default-topology-index = <0>;
		};
	};
};

&dsi_sim_dsc_375_cmd {
	qcom,dsi-select-clocks = "mux_byte_clk0", "mux_pixel_clk0";
	qcom,mdss-dsi-display-timings {
		timing@0 { /* 1080p */
			qcom,mdss-dsi-panel-phy-timings = [00 00 04 04 08 07 05
				05 03 02 04 00 0e 09];
			qcom,display-topology = <1 1 1>;
			qcom,default-topology-index = <0>;
		};

		timing@1 { /* qhd */
			qcom,mdss-dsi-panel-phy-timings = [00 07 02 02 04 04 02
				02 01 02 04 00 08 07];
			qcom,display-topology = <1 1 1>,
						<2 2 1>, /* dsc merge */
						<2 1 1>; /* 3d mux */
			qcom,default-topology-index = <0>;
		};
	};
};

&dsi_sim_dsc_10b_cmd {
	qcom,dsi-select-clocks = "mux_byte_clk0", "mux_pixel_clk0";
	qcom,mdss-dsi-display-timings {
		timing@0 { /* QHD 60fps */
			qcom,mdss-dsi-panel-phy-timings = [00 1c 08 07 23 22 07
				07 05 02 04 00 18 17];
			qcom,display-topology = <1 1 1>;
			qcom,default-topology-index = <0>;
		};

		timing@1 { /* 1080 60fps */
			qcom,mdss-dsi-panel-phy-timings = [00 1e 08 07 24 22 08
				08 05 02 04 00 19 18];
			qcom,display-topology = <1 1 1>,
						<2 2 1>, /* dsc merge */
						<2 1 1>; /* 3d mux */
			qcom,default-topology-index = <0>;
		};

		timing@2 { /* QHD 90fps */
			qcom,mdss-dsi-panel-phy-timings = [00 1c 08 07 23 22 07
				07 05 02 04 00 18 17];
			qcom,display-topology = <1 1 1>;
			qcom,default-topology-index = <0>;
		};
	};
};

&dsi_dual_sim_cmd {
	qcom,dsi-select-clocks = "mux_byte_clk0", "mux_pixel_clk0";
	qcom,mdss-dsi-display-timings {
		timing@0 { /* 5K 60FPS cmd mode*/
			qcom,mdss-dsi-panel-phy-timings = [00 3d 11 10 1b 17 11
				11 0c 02 04 00 30 15];
			qcom,display-topology = <2 0 2>;
			qcom,default-topology-index = <0>;
		};

		timing@1 { /* FHD 60FPS cmd mode*/
			qcom,mdss-dsi-panel-phy-timings = [00 0d 03 03 06 06 04
				04 02 02 04 00 0c 08];
			qcom,display-topology = <2 0 2>;
			qcom,default-topology-index = <0>;
		};

		timing@2 { /* WQHD 60FPS cmd mode*/
			qcom,mdss-dsi-panel-phy-timings = [00 0a 03 03 05 05 03
				03 01 02 04 00 0a 08];
			qcom,display-topology = <2 0 2>,
						<1 0 2>;
			qcom,default-topology-index = <0>;
		};

		timing@3 { /* 4K 60FPS cmd mode*/
			qcom,mdss-dsi-panel-phy-timings = [00 13 05 05 09 08 05
				05 03 02 04 00 10 0a];
			qcom,display-topology = <2 0 2>;
			qcom,default-topology-index = <0>;
		};
	};
};

&dsi_dual_sim_vid {
	qcom,dsi-select-clocks = "mux_byte_clk0", "mux_pixel_clk0";
	qcom,mdss-dsi-display-timings {
		timing@0 {
			qcom,mdss-dsi-panel-phy-timings = [00 17 07 06 0b 0a 07
				07 07 04 02 00 14 0b];
			qcom,display-topology = <2 0 2>,
						<1 0 2>;
			qcom,default-topology-index = <0>;
		};
	};
};

&dsi_dual_sim_dsc_375_cmd {
	qcom,dsi-select-clocks = "mux_byte_clk0", "mux_pixel_clk0";
	qcom,mdss-dsi-display-timings {
		timing@0 { /* 4k  30 FPS*/
			qcom,mdss-dsi-panel-phy-timings = [00 09 03 03 05 05 03
				03 01 02 04 00 09 08];
			qcom,display-topology = <2 2 2>;
			qcom,default-topology-index = <0>;
		};

		timing@1 { /* 4k  60 FPS*/
			qcom,mdss-dsi-panel-phy-timings = [00 12 05 05 09 08 05
				05 03 02 04 00 10 0a];
			qcom,display-topology = <2 2 2>;
			qcom,default-topology-index = <0>;
		};

		timing@2 { /* 4k  90 FPS*/
			qcom,mdss-dsi-panel-phy-timings = [00 1a 08 07 0c 0b 08
				08 05 02 04 00 16 0c];
			qcom,display-topology = <2 2 2>;
			qcom,default-topology-index = <0>;
		};

		timing@3 { /* 4k  120 FPS*/
			qcom,mdss-dsi-panel-phy-timings = [00 23 0a 09 10 0e 0a
				0a 07 02 04 00 1d 0e];
			qcom,display-topology = <2 2 2>;
			qcom,default-topology-index = <0>;
		};

		timing@4 { /* 1080  30 FPS*/
			qcom,mdss-dsi-panel-phy-timings = [01 04 01 01 03 03 01
				01 01 02 04 00 05 06];
			qcom,display-topology = <2 2 2>;
			qcom,default-topology-index = <0>;
		};

		timing@5 { /* 1080  60 FPS*/
			qcom,mdss-dsi-panel-phy-timings = [00 07 02 02 04 04 02
				02 01 02 04 00 08 07];
			qcom,display-topology = <2 2 2>;
			qcom,default-topology-index = <0>;
		};

		timing@6 { /* 1080  90 FPS*/
			qcom,mdss-dsi-panel-phy-timings = [00 09 03 03 05 05 03
				03 01 02 04 00 09 08];
			qcom,display-topology = <2 2 2>;
			qcom,default-topology-index = <0>;
		};

		timing@7 { /* 1080  120 FPS*/
			qcom,mdss-dsi-panel-phy-timings = [00 0d 03 03 06 06 04
				04 02 02 04 00 0c 08];
			qcom,display-topology = <2 2 2>;
			qcom,default-topology-index = <0>;
		};

		timing@8 { /* qhd 30 FPS*/
			qcom,mdss-dsi-panel-phy-timings = [00 06 01 01 03 03 02
				01 00 02 04 00 06 06];
			qcom,display-topology = <2 2 2>;
			qcom,default-topology-index = <0>;
		};

		timing@9 { /* qhd 60 FPS*/
			qcom,mdss-dsi-panel-phy-timings = [00 09 03 03 05 05 03
				03 01 02 04 00 09 08];
			qcom,display-topology = <2 2 2>;
			qcom,default-topology-index = <0>;
		};

		timing@10 { /* qhd  90 FPS*/
			qcom,mdss-dsi-panel-phy-timings = [00 0e 03 04 07 06 04
				04 02 02 04 00 0c 09];
			qcom,display-topology = <2 2 2>;
			qcom,default-topology-index = <0>;
		};

		timing@11 { /* qhd 120 FPS*/
			qcom,mdss-dsi-panel-phy-timings = [00 11 05 05 08 08 05
				05 03 02 04 00 0f 0a];
			qcom,display-topology = <2 2 2>;
			qcom,default-topology-index = <0>;
		};

		timing@12 { /* 5k */
			qcom,mdss-dsi-panel-phy-timings = [00 17 07 06 0b 0a 07
				07 04 02 04 00 14 0b];
			qcom,display-topology = <2 2 2>;
			qcom,default-topology-index = <0>;
		};

		timing@13 { /* 720p 30 FPS */
			qcom,mdss-dsi-panel-phy-timings = [03 03 00 01 02 02 01
				01 00 02 04 00 04 06];
			qcom,display-topology = <2 2 2>;
			qcom,default-topology-index = <0>;
		};

		timing@14 { /* 720p 60 FPS */
			qcom,mdss-dsi-panel-phy-timings = [01 05 01 01 03 03 01
				01 01 02 04 00 06 06];
			qcom,display-topology = <2 2 2>;
			qcom,default-topology-index = <0>;
		};

		timing@15 { /* 720p 90 FPS */
			qcom,mdss-dsi-panel-phy-timings = [00 06 02 02 04 04 02
				02 01 02 04 00 07 07];
			qcom,display-topology = <2 2 2>;
			qcom,default-topology-index = <0>;
		};

		timing@16 { /* 720 120 FPS */
			qcom,mdss-dsi-panel-phy-timings = [00 08 02 02 04 04 03
				03 01 02 04 00 08 07];
			qcom,display-topology = <2 2 2>;
			qcom,default-topology-index = <0>;
		};

		timing@17 { /* 1080 144FPS cmd mode*/
			qcom,mdss-dsi-panel-phy-timings = [00 16 05 05 14 13 06
				06 06 02 04 00 13 0a];
			qcom,display-topology = <2 2 2>;
			qcom,default-topology-index = <0>;
		};

		timing@18 { /* WQHD  144 FPS*/
			qcom,mdss-dsi-panel-phy-timings = [00 23 0a 09 10 0e 0a
				0a 07 02 04 00 1d 0e];
			qcom,display-topology = <2 2 2>;
			qcom,default-topology-index = <0>;
		};
	};
};

&dsi_sim_sec_hd_cmd {
	qcom,dsi-select-sec-clocks = "mux_byte_clk1", "mux_pixel_clk1";
	qcom,mdss-dsi-display-timings {
		timing@0 {
			qcom,mdss-dsi-panel-phy-timings = [00 1e 08 07 24 22
				08 08 05 02 04 00 19 17];
			qcom,display-topology = <1 0 1>;
			qcom,default-topology-index = <0>;
		};
	};
};

&dsi_ext_bridge_1080p {
	qcom,dsi-select-clocks = "mux_byte_clk0", "mux_pixel_clk0";
	qcom,mdss-dsi-display-timings {
		timing@0 {
			qcom,mdss-dsi-panel-phy-timings = [00 1e 08 07 18 22 08
				08 08 02 04 00 1a 0c];
			qcom,display-topology = <1 0 1>;
			qcom,default-topology-index = <0>;
		};
	};
};
